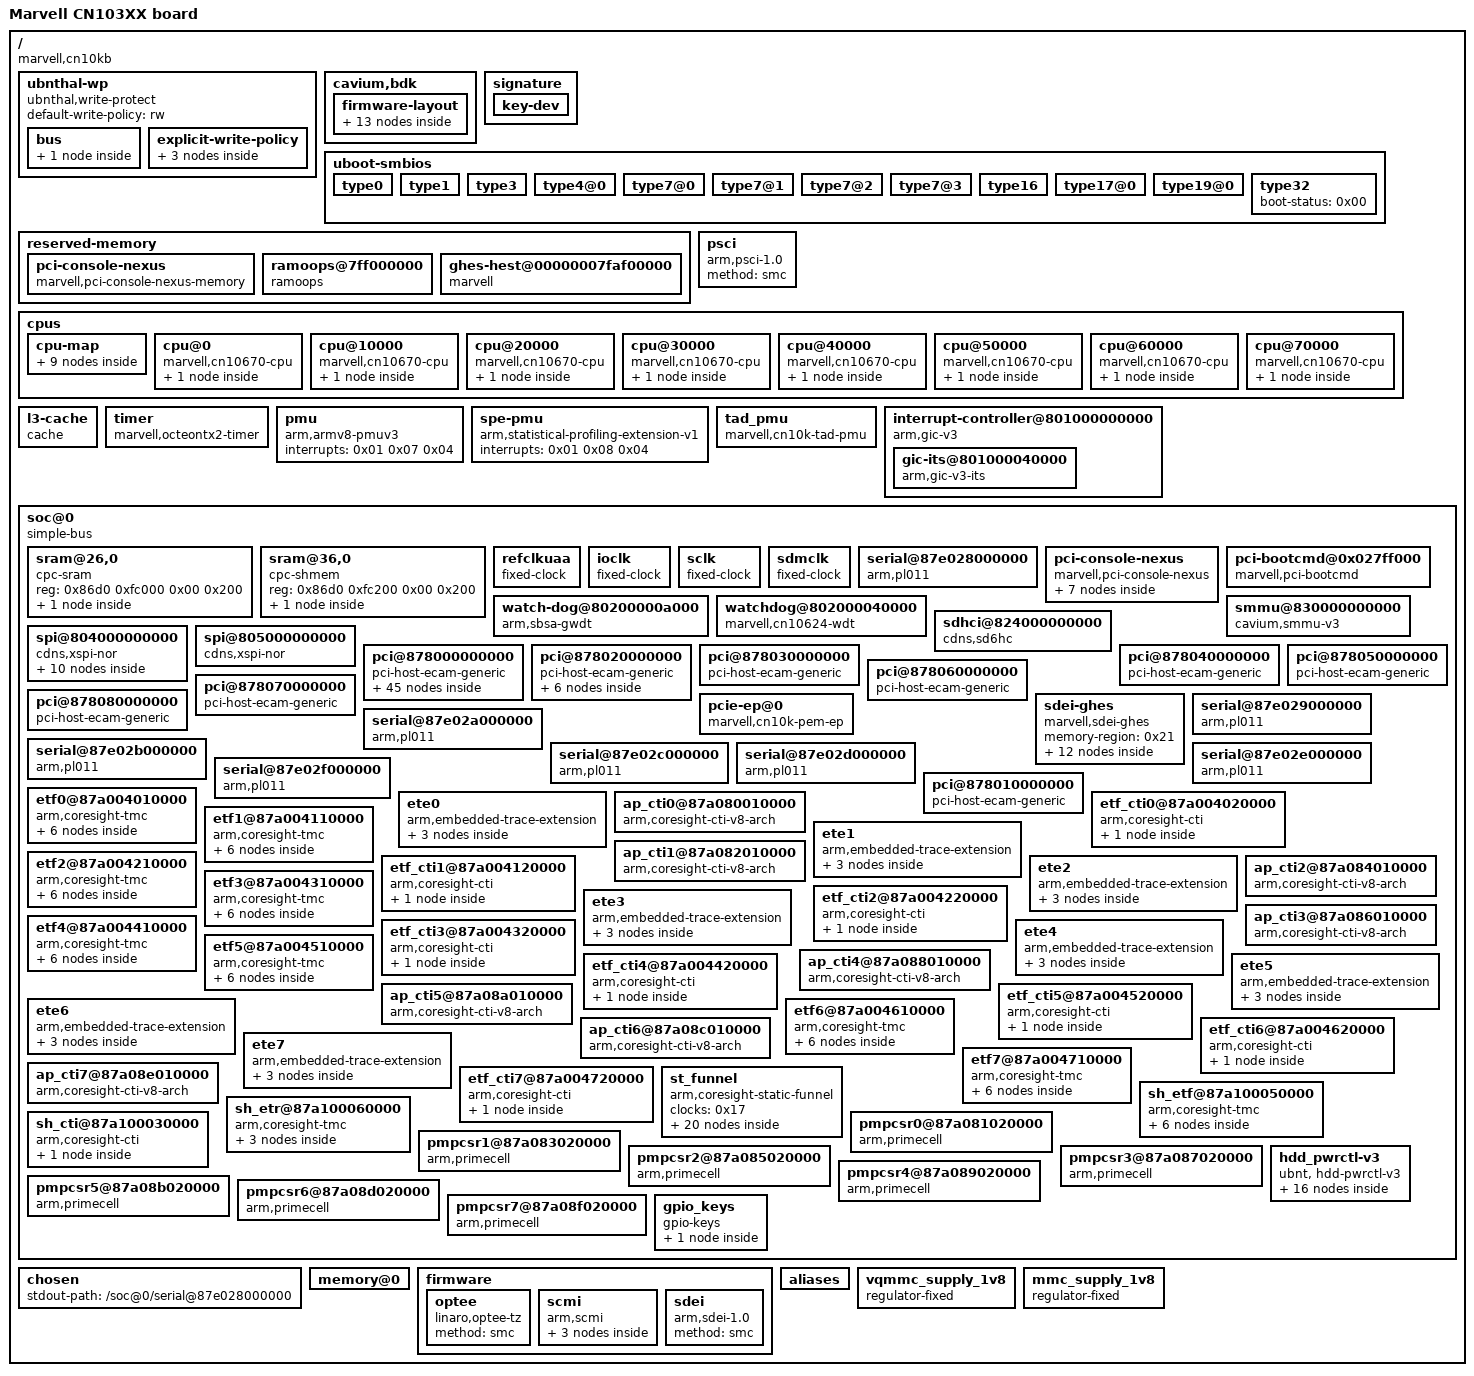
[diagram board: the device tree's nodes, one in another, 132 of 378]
/dts-v1/;

/ {
	model = "Marvell CN103XX board";
	compatible = "marvell,cn10kb";
	interrupt-parent = <0x01>;
	#address-cells = <0x02>;
	#size-cells = <0x02>;

	ubnthal-wp {
		compatible = "ubnthal,write-protect";
		default-write-policy = "rw";

		bus {

			spi@0 {
				bus = "*.spi";
				default-write-policy = "rw";
			};
		};

		explicit-write-policy {

			mtd {

				partition@0 {
					label = "Factory";
					write-policy = "ro";
				};

				partition@1 {
					label = "EEPROM";
					write-policy = "ro";
				};
			};
		};
	};

	cavium,bdk {
		TWSI0-HIDE-NSEC = "0";
		EBF-CONFIG-PCIE-DISABLE-HOST-BAR0-WINDOWING = "0";
		APA-WATCHDOG-TIMEOUT = "0";
		DDR-PRESERVE-CORESIGHT-REGION-SIZE = "0";
		UART-RX-DISABLE-UPON-BOOT = [00];
		PHASE-ADAPT-CAL = "0xf";
		LOAD-EHSM-PIE-FW = "0";
		SPI0-CS0-FLASH-SECTOR-64K = "0";
		RESET-COUNT-PERSIST = "0";
		EBF-CONFIG-ATF-TIMESTAMP = "0";
		EBF-CONFIG-ATF-TRACE-LEVEL = "0";
		EBF-CONFIG-ATF-TRACE-MODULES = "0";
		PBUS-TIM = "0";
		PBUS-CFG = "0";
		UAA0-DRIVE = "3";
		UAA0-SLEW = "3";
		TWSI0-DRIVE = "1";
		TWSI0-SLEW = "2";
		AVS-DRIVE = "3";
		AVS-SLEW = "3";
		GPIO-POLARITY-REMAP-GPIO0 = "0";
		GPIO-PIN-SELECT-REMAP-GPIO0 = "-1";
		GPIO-DRIVE = "2";
		GPIO-SLEW = "3";
		GPIO-POLARITY-GPIO0 = "0";
		GPIO-PIN-SELECT-GPIO0 = "-1";
		DIS-TAD-DQ = "0";
		MKCB-CHANNEL-LENGTH = "0";
		MKCB-CHANNEL-ADDR = "0";
		KTOM-CHANNEL-LENGTH = "0";
		KTOM-CHANNEL-ADDR = "0";
		SCP-NMI-GPIO = "-1";
		MCP-TWSI-TARGET-ADDR = "0x77";
		MCP-TWSI-TARGET-BUS = "-1";
		SCP-SAFE-MODE = "1";
		SCP-FAIL-ACTION = "0";
		SCP-FAIL-TIMEOUT = "0xa";
		SCP-ACTIVE-THRESHOLD = "0x3e8";
		SCP-WAKEUP-MODE = "1";
		SCP-FORCE-SECONDARY-BOOT = "0";
		SCP-MCP-DISABLE = "0";
		SCP-UART-REDIRECT-NUM = "0xf";
		SCP-UART-NUM = "1";
		POWER-LIMIT-GPIO-INVERT = "0";
		POWER-LIMIT-GPIO-PIN = "0";
		DVFS-THERMAL-HOT-BACKOFF = "0x32";
		DVFS-THERMAL-HOT = "0x64";
		DVFS-POWER-CONTROL-MODE = "5";
		DVFS-POWER-BUDGET = "0x64";
		VDD-SYS-COMPENSATION = "0x64";
		VDD-SYS-TOLERANCE = "0x1d";
		VDD-CORE-COMPENSATION = "0x64";
		VDD-CORE-TOLERANCE = "0x1d";
		SYNCE-MODE = "1";
		NCLK-FREQ = "0x190";
		NETCLK-FREQ = "0x320";
		IOCLK-FREQ = "0x320";
		CPTCLK-FREQ = "0x1f4";
		DSPCLK-FREQ = "0x1f4";
		BCLK-FREQ = "0x1f4";
		SCLK-FREQ-MIN = "0x1f4";
		CORECLK-FREQ-MIN = "0x1f4";
		VRM-TEMP-HIGH = "0x6e";
		VRM-TEMP-TRIP = "0x82";
		USB-RX-SIGDET-LF-THRESH-EN = "1";
		USB-RX-SIGDET-LF-THRESH = "5";
		USB-SET-SS-SPEED = "2";
		USB-TX-DEEMPH-3 = "0xf80";
		USB-TX-DEEMPH-2 = "0x8d80";
		USB-TX-DEEMPH-1 = "0xe45";
		USB-TX-DEEMPH-10G = "0x8c45";
		USB-TX-DEEMPH-5G = "0xacc0";
		USB-DISABLE-PORTS = "0";
		USB-PWR-GPIO-POLARITY = "1";
		USB-PWR-GPIO = "-1";
		DDR-DRAM-CONTROL-TEST-FLAGS = "4";
		DDR-DRAM-CONTROL-TEST-LENGTH = "0x80000000";
		DDR-DRAM-CONTROL-START-ADDR = "0";
		DDR-DRAM-TEST-SELECTIONS = "0";
		DDR-PRESERVE-ECC-CHECK = "0";
		DDR-PRESERVE-REGION-DIAG = "0";
		EBF-CONFIG-DDR5-SCRUB-EN = "0";
		DDR-MBIST-STOP-ON-UNREPAIRABLE-FAIL = "0";
		DDR-DRAM-MPPR = "0";
		DDR-DRAM-MBIST = "0";
		EBF_CONFIG_DDR5_PPR_ROW = "0x40000";
		EBF_CONFIG_DDR5_PPR_BA = "0";
		EBF_CONFIG_DDR5_PPR_BG = "0";
		EBF_CONFIG_DDR5_PPR_DEVICE = "0";
		EBF_CONFIG_DDR5_PPR_RANK = "0";
		EBF_CONFIG_DDR5_PPR_CHANNEL = "0";
		DDR-PHY-VREF-CA-SWEEP-MAX = "0x10";
		DDR-PHY-VREF-CA-SWEEP-MIN = "0x40";
		DDR-PHY-VREF-CS-SWEEP-MAX = "0x10";
		DDR-PHY-VREF-CS-SWEEP-MIN = "0x40";
		DDR-PHY-USE-LFSR0-ONLY = "0";
		DDR-PHY-REPEAT-RX-TRAIN = "0";
		DDR-PHY-CA-TRAIN-OPT = "0x10";
		DDR-PHY-IS-HIGH-VDD = "0";
		EBF-CONFIG-DDR5-ECC-EN = "1";
		DDR4-TX2D-TRAIN-OPT = "0";
		DDR4-RX2D-TRAIN-OPT = "0";
		DDR-DRAM-TYPE = "0";
		DDR4-FGR-MODE = "0";
		DDR4-VREF-DQ-VALUE = "0";
		DDR4-VREF-DQ-RANGE = "0";
		DDR4-WR-CRC = "0";
		DDR4-MEM-RTT-PARK-DUAL-RANK = "0";
		DDR4-MEM-RTT-PARK-SINGLE-RANK = "0";
		DDR4-MEM-RTT-WR-DUAL-RANK = "0";
		DDR4-MEM-RTT-WR-SINGLE-RANK = "0";
		DDR4-OUTPUT-DRV = "0";
		DDR4-MEM-RTT-NOM-DUAL-RANK = "0";
		DDR4-MEM-RTT-NOM-SINGLE-RANK = "0";
		DDR4-RD-PREAMBLE = "0";
		DDR4-WR-PREAMBLE = "0";
		DDR4-DDRC-2T-MODE = "0";
		DDR4-DDRC-T-REFI = "0";
		DDR-MCT-KEY-127-96 = "0";
		DDR-MCT-KEY-95-64 = "0";
		DDR-MCT-KEY-63-32 = "0";
		DDR-MCT-KEY-31-0 = "0";
		DDR4-MCT-CMD-TYPE = "0";
		DDR-SPD-ADDR = "0";
		DDR-PERFWR1 = "0x8000400";
		DDR-PERFLPR1 = "0x800007f";
		DDR-PERFHPR1 = "0x8000001";
		DDR-LPRNUMENTRIES = "0x3e";
		DDR-PCHBCBUSYW = "0x1408008";
		DDR-PCHBCBUSYL = "0x120600c";
		DDR-PCHBCBUSYH = "0x501c02";
		DDR-PCHBPROTQCTL = "0";
		DDR-PCHBWQOS1 = "0x380038";
		DDR-PCHBRQOS1 = "0x380038";
		DDR-PCHBWQOS0 = "0x1000a05";
		DDR-PCHBRQOS0 = "0xe00";
		DDR-PPR-EPRC-TH = "0x80";
		DDR-PPR-REPAIR-ROWS-OFF = "1";
		DDR-PPR-STAT-EN = "1";
		DDR-PPR-EN = "0";
		PORTM-SCH = "-1";
		ETHERNET-PERSIST-SETTINGS-IGNORE = "0";
		PORTM-802-3AP-FEC-REQ = "0";
		PORTM-802-3AP-FEC-ABIL = "0";
		PORTM-802-3AP-MASTER-LANE = "0";
		PORTM-LANE-TX-POST = "-1";
		PORTM-LANE-TX-PRE1 = "-1";
		PORTM-LANE-TX-PRE2 = "-1";
		PORTM-LANE-TX-MAIN = "-1";
		PORTM-LANE-TX-POLARITY = "0";
		PORTM-LANE-RX-POLARITY = "0";
		PORTM-LANE-TX-PRECODE-EN = "0";
		PORTM-LANE-RX-PRECODE-EN = "0";
		PORTM-RX-TERMINATION = "0";
		PORTM-FEC = "0";
		PORTM-MAC-TO-SERDES-MAP = "-1";
		REF-CLK-TERM = "0";
		SDP-VF-RINGS = "8";
		SDP-PF-RINGS = "8";
		PCIE-EP-HAS-PHC = "0";
		PCIE-HOST-STREAM-IDS-PEM0 = "0x30000";
		PCIE-ALLOW-HOST-TO-ACCESS-OCTEON-MEM = "0";
		PCIE-EP-SRIOV-BAR0 = "-1";
		PCIE-EP-SRIOV-DEV = "0xb903";
		PCIE-EP-NUM-VFS = "8";
		PCIE-EP-ROM-SIZE = "0";
		PCIE-EP-BAR0-SIZE = "-1";
		PCIE-EP-SUBSYS = "0xb900177d";
		PCIE-EP-REV = "0x2800000";
		PCIE-EP-ID = "0xb900177d";
		PCIE-EP-NUM-PFS = "1";
		PCIE-GEN2-LOW-SWING-MODE = "0";
		PCIE-MAX-LINK-SPEED = "GEN5";
		PCIE-RC-HOTPLUG-BUS-COUNT = "1";
		PCIE-RC-HOTPLUG = "0";
		PCIE-PHYSICAL-SLOT = "-1";
		PCIE-RC-TX-INITIAL-PRESET-GEN5 = "9";
		PCIE-RC-TX-INITIAL-PRESET-GEN4 = "5";
		PCIE-RC-TX-INITIAL-PRESET-GEN3 = "7";
		PCIE-GEN2-DEEMPHASIS = "0";
		PCIE-PRESET-REQUEST-VECTOR-GEN5 = "0x200";
		PCIE-PRESET-REQUEST-VECTOR-GEN4 = "0x20";
		PCIE-PRESET-REQUEST-VECTOR-GEN3 = "0x80";
		PCIE-ORDERING = "0";
		PCIE-ENHANCED-ALLOCATION = "1";
		SKIP-TIM-VERSION = "0";
		EBF-CONFIG-TRACE = "0";
		EBF-COREMASK = "0";
		PCIE-REF-CLOCK = "0";
		SWITCH-RESET = "1";
		SWITCH-MICROINIT = "1";
		SWITCH-DEV-INTERRUPT-PIN-SMI0 = "-1";
		SWITCH-DEV-INIT-DONE-PIN-SMI0 = "-1";
		SWITCH-SLAVE-ADDR-SMI0 = "7";
		SWITCH-SA-ALDRIN3M-PEM-PORT = "-1";
		SWITCH-SA-SMI-BUS = "-1";
		SWITCH-MCM-SMI-BUS = "-1";
		RETIMER-GSERM-MUX0 = "-1";
		WATCHDOG-TIMEOUT = "0";
		BOARD-MAC-ADDRESS-ID0 = "0";
		BOARD-MAC-ADDRESS-ID-NUM = "0";
		BOARD-MAC-ADDRESS-NUM = "0";
		BOARD-MAC-ADDRESS = "0x20fb7000000";
		BOARD-SERIAL = "unknown";
		BOARD-REVISION = "sr1";
		BOARD-MODEL = "unvr-ent";
		PCIE-EP-OVERRIDE-IDENTITY = "0";
		SCP-FAILSAFE-TIMEOUT = "60";
		DDR-SPD-ADDR.DSS0 = "0x3050";
		DDR-PRESERVE-RAMOOPS-REGION-SIZE = "16";
		DDR-PRESERVE-USERDEF-REGION-SIZE = "0";
		PORTM-MODE.P3 = "XFI";
		PORTM-MODE.P2 = "XFI";
		PORTM-MODE.P1 = "DISABLED";
		PORTM-MODE.P0 = "XFI";
		GPIO-PIN-SELECT-GPIO43 = "0x2a3";
		GPIO-PIN-SELECT-GPIO42 = "0x297";
		GPIO-PIN-SELECT-GPIO37 = "0x2a7";
		GPIO-PIN-SELECT-GPIO36 = "0x29b";
		GPIO-PIN-SELECT-GPIO35 = "0x2a6";
		GPIO-PIN-SELECT-GPIO34 = "0x29a";
		GPIO-PIN-SELECT-GPIO33 = "0x2a5";
		GPIO-PIN-SELECT-GPIO32 = "0x299";
		GPIO-PIN-SELECT-GPIO31 = "0x2a4";
		GPIO-PIN-SELECT-GPIO30 = "0x298";
		GPIO-PIN-SELECT-GPIO29 = "0x2a2";
		GPIO-PIN-SELECT-GPIO28 = "0x296";
		GPIO-PIN-SELECT-GPIO27 = "0x271";
		GPIO-PIN-SELECT-GPIO26 = "0x270";
		GPIO-PIN-SELECT-GPIO24 = "0x274";
		GPIO-PIN-SELECT-GPIO23 = "0x256";
		GPIO-PIN-SELECT-GPIO22 = "0x254";
		GPIO-PIN-SELECT-GPIO21 = "0x255";
		GPIO-PIN-SELECT-GPIO20 = "0x253";
		GPIO-PIN-SELECT-GPIO19 = "0x27b";
		GPIO-PIN-SELECT-GPIO18 = "0x27a";
		GPIO-PIN-SELECT-GPIO17 = "0x279";
		GPIO-PIN-SELECT-GPIO16 = "0x278";
		PCIE-REF-CLOCK.PORT0 = "1";
		PCIE-MAX-LINK-SPEED.PORT5 = "GEN3";
		PCIE-MAX-LINK-SPEED.PORT4 = "GEN3";
		PCIE-MAX-LINK-SPEED.PORT3 = "GEN3";
		PCIE-MAX-LINK-SPEED.PORT2 = "GEN3";
		PCIE-MAX-LINK-SPEED.PORT1 = "GEN3";
		PCIE-MAX-LINK-SPEED.PORT0 = "GEN3";
		PCIE-MODE.PORT5 = "PCIE_X1";
		PCIE-MODE.PORT1 = "PCIE_X1";
		PCIE-MODE.PORT4 = "PCIE_X1";
		PCIE-MODE.PORT3 = "PCIE_X1";
		PCIE-MODE.PORT2 = "PCIE_X1";
		PCIE-MODE.PORT0 = "PCIE_X1";
		SCLK-FREQ-MAX = "1000";
		CORECLK-FREQ-MAX = "2500";
		EBF-BOOT-MENU-TIMEOUT = "10";
		DDR5-DFE-GAIN-BIAS = "3";
		DDR5-TX2D-TRAIN-OPT = "1";
		DDR5-RX2D-TRAIN-OPT = "1";
		DDR5-MEM-RTT-NOM-RD = "3";
		DDR5-MEM-RTT-NOM-WR = "3";
		DDR5-MEM-RTT-WR-DUAL-RANK = "3";
		DDR5-MEM-RTT-WR-SINGLE-RANK = "4";
		DDR5-MEM-RTT-PARK = "7";
		DDR5-MEM-DQS-RTT-PARK = "5";
		DDR5-MEM-CA-ODT-GRP-B-DUAL-RANK = "4";
		DDR5-MEM-CA-ODT-GRP-A-DUAL-RANK = "1";
		DDR5-MEM-CA-ODT-GRP-B-SINGLE-RANK = "5";
		DDR5-MEM-CA-ODT-GRP-A-SINGLE-RANK = "2";
		DDR5-MEM-CS-ODT-GRP-B = "5";
		DDR5-MEM-CK-ODT-GRP-B = "5";
		DDR5-MEM-CS-ODT-GRP-A = "2";
		DDR5-MEM-CK-ODT-GRP-A = "2";
		DDR5-MEM-VREF-CS = "0xad";
		DDR5-MEM-VREF-CA = "0x2d";
		DDR5-MEM-VREF-DQ = "0x37";
		DDR-X16-BYTE-SWAP-BIT-MASK = "0";
		DDR-PHY-ADV-TRAIN-OPT = "0x28";
		DDR-PHYCFG-SETUP-HOLD = "0";
		DDR-PHY-TX-SLEW-FALL-CK = "0";
		DDR-PHY-TX-SLEW-RISE-CK = "0";
		DDR-PHY-TX-SLEW-FALL-AC = "1";
		DDR-PHY-TX-SLEW-RISE-AC = "1";
		DDR-PHY-TX-SLEW-FALL-DQ = "0";
		DDR-PHY-TX-SLEW-RISE-DQ = "0";
		DDR-PHY-INITIAL-VREF = "90";
		DDR-PHY-HDT-CTRL = "0xC8";
		DDR-PHY-CS-TX-IMP = "30";
		DDR-PHY-CA-TX-IMP = "30";
		DDR-PHY-CK-TX-IMP = "30";
		DDR-PHY-TX-IMP = "30";
		DDR-PHY-ODT-M_ALERT-IMP = "120";
		DDR-PHY-ODT-IMP-DUAL-RANK = "40";
		DDR-PHY-ODT-IMP-SINGLE-RANK = "60";
		DDR5-TCR-EN = "0";
		DDR5-RD-PREAMBLE = "3";
		DDR5-WR-POSTAMBLE = "1";
		DDR5-WR-PREAMBLE = "2";
		DDR5-RD-POSTAMBLE = "1";
		DDR-RD-CRC-EN = "0";
		DDR-WR-CRC-EN = "0";
		DDR5-DDRC-2N-MODE = "0";
		DDR5-REFRESH-MODE-TEMP = "0";
		DDR5-REFRESH-MODE = "1";
		DDR5-PAGE-CLOSE-TIMER = "0";
		DDR5-PAGE-CLOSE-EN = "1";
		DDR-DDRC-DATA-BUS-WIDTH = "0";
		DDR-OUTPUT-DRV-IMP = "0";
		DDR-MCT-DATA-BUS-WIDTH = "1";
		DDR-MCT-ENC-KEY-SCRAMBLE = "1";
		DDR5-MCT-BURST-CHOP-EN = "0";
		DDR5-MCT-BURST-LENGTH = "1";
		DDR-MCT-EN = "0";
		DDR-MCT-WIN-ADDR-HIGH = "0xFFFFFFFFFFFFF";
		DDR-MCT-WIN-ADDR-LOW = "0x0";
		DDR-MCT-NUM-OF-WIN = "1";
		DDR-MCT-ENCRYPTION-EN = "0";
		DDR-SPEED = "4800";
		DDR-DMC-MASK = "3";
		EBF-VERSION = "12.23.12-5550707, Branch: (HEAD detached at 5550707), Built: Mon, 11 Mar 2024 09:50:36 +0000";
		RESET-COUNT-COLD = "0";
		RESET-COUNT-WARM = "0";
		RESET-COUNT-SCP-WDOG = "0";
		RESET-COUNT-CORE-WDOG = "0";
		RESET-COUNT-MCP-WDOG = "0";
		RESET-COUNT-ECP-WDOG = "0";
		BOOT-DEVICE = "SPI0_CS0";
		EBF-BOOT-PATH-OPTION = "0";
		CHIP-SKU = "MV-CN10208-A0-HF240AG-xxxx-SCP";
		CHIP-SERIAL = " ";
		CHIP-UNIQUE-ID = "00000000000000000000";
		PCIE-EP-INITIALIZE-AFTER-MEM-CONFIG = "0";
		DDR-DMC-CH-SIZE = <0x4000 0x4000>;
		DDR-WAS-PRESERVED = "1";
		DDR-SPD-DATA.DSS0 = <0x30101203 0x4002062 0x00 0xb2120d00 0x00 0x6501f203 0x7aad0000 0x803e 0x803e803e 0x7d80bb 0x30752701 0xa0008200 0x00 0xd400 0xd400 0xd400 0xd400 0x8813 0x8881308 0x204e2010 0x2710a42c 0x20102710 0xc409044c 0x1d0c0000 0x00 0x00 0x00 0x00 0x00 0x00 0x00 0x00 0x00 0x00 0x00 0x00 0x00 0x00 0x00 0x00 0x00 0x00 0x00 0x00 0x00 0x00 0x00 0x00 0x10008632 0x80158a8c 0x82130000 0x00 0x00 0x00 0x00 0x00 0x00 0xf11 0x1820822 0x00 0x00 0x00 0x00 0x00 0x00 0x00 0x00 0x00 0x00 0x00 0x00 0x00 0x00 0x00 0x00 0x00 0x00 0x00 0x00 0x00 0x00 0x00 0x00 0x00 0x00 0x00 0x00 0x00 0x00 0x00 0x00 0x00 0x00 0x00 0x00 0x00 0x00 0x00 0x00 0x00 0x00 0x00 0x00 0x00 0x00 0x00 0x00 0x00 0x00 0x00 0x00 0x00 0x00 0x00 0x00 0x00 0x00 0x00 0x00 0x00 0x00 0x00 0x00 0x00 0x00 0x00 0x00 0x70a8 0x1980123 0x45ef075a 0xf1434244 0x35365334 0x36424438 0x48412d33 0x32202020 0x20202020 0x20202020 0x20202000 0x80ad4100 0x8313031 0x36323035 0x34000000 0x00 0x00 0x00 0x00 0x00 0x00 0x1000000 0x00 0x00 0x00 0x01 0x1000000 0x00 0x88 0x00 0x00 0x00 0x00>;

		firmware-layout {
			#size-cells = <0x01>;
			#address-cells = <0x01>;

			tee.bin@00810000 {
				reg = <0x810000 0x250000>;
				description = "tee.bin";
				os = "arm-trusted-firmware";
				arch = "arm64";
				compression = "none";
				type = "firmware";
			};

			npc_mkex-cn10xx.fw@007b0000 {
				flags = <0x00>;
				version = "01.0A.00 20240201-1636 00000000";
				customer-version = <0x00>;
				time = <0x10240000>;
				date = <0x7e80201>;
				revision = <0x10a0000>;
				reg = <0x7b0000 0x60000>;
				description = "npc_mkex-cn10xx.fw";
				compression = "none";
				type = "firmware";
			};

			u-boot-nodtb.bin@00660000 {
				flags = <0x00>;
				version = "0B.17.0C 20240111-0222 00000000";
				customer-version = <0x00>;
				time = <0x2160000>;
				date = <0x7e8010b>;
				revision = <0xb170c00>;
				reg = <0x660000 0x150000>;
				description = "u-boot-nodtb.bin";
				os = "arm-trusted-firmware";
				arch = "arm64";
				compression = "none";
				type = "firmware";
			};

			bl31.bin@00540000 {
				flags = <0x00>;
				version = "0B.17.0C 20240111-0222 00000000";
				customer-version = <0x00>;
				time = <0x2160000>;
				date = <0x7e8010b>;
				revision = <0xb170c00>;
				reg = <0x540000 0x120000>;
				description = "bl31.bin";
				os = "arm-trusted-firmware";
				arch = "arm64";
				compression = "none";
				type = "firmware";
			};

			bl2.bin@004C0000 {
				flags = <0x00>;
				version = "0B.17.0C 20240111-0222 00000000";
				customer-version = <0x00>;
				time = <0x2160000>;
				date = <0x7e8010b>;
				revision = <0xb170c00>;
				reg = <0x4c0000 0x80000>;
				description = "bl2.bin";
				os = "arm-trusted-firmware";
				arch = "arm64";
				compression = "none";
				type = "firmware";
			};

			gserp-cn10xx.fw@00490000 {
				flags = <0x00>;
				version = "01.01.0C 20240201-1636 00000000";
				customer-version = <0x00>;
				time = <0x10240000>;
				date = <0x7e80201>;
				revision = <0x1010c00>;
				reg = <0x490000 0x30000>;
				description = "gserp-cn10xx.fw";
				os = "arm-trusted-firmware";
				arch = "custom";
				compression = "none";
				type = "firmware";
			};

			gserm-cn10xx.fw@00460000 {
				flags = <0x00>;
				version = "01.01.0A 20240201-1636 00000000";
				customer-version = <0x00>;
				time = <0x10240000>;
				date = <0x7e80201>;
				revision = <0x1010a00>;
				reg = <0x460000 0x30000>;
				description = "gserm-cn10xx.fw";
				os = "arm-trusted-firmware";
				arch = "custom";
				compression = "none";
				type = "firmware";
			};

			init.bin@00100000 {
				flags = <0x00>;
				version = "0C.17.0C 20240311-0951 00000000";
				customer-version = <0x00>;
				time = "\t3", "";
				date = <0x7e8030b>;
				revision = <0xc170c00>;
				reg = <0x100000 0x360000>;
				description = "init.bin";
				os = "arm-trusted-firmware";
				arch = "arm64";
				compression = "none";
				type = "firmware";
			};

			ecp_bl1.bin@000D0000 {
				flags = <0x00>;
				version = "0C.17.0C 20231209-2323 00000000";
				customer-version = <0x00>;
				time = <0x17170000>;
				date = <0x7e70c09>;
				revision = <0xc170c00>;
				reg = <0xd0000 0x30000>;
				description = "ecp_bl1.bin";
				os = "arm-trusted-firmware";
				arch = "mips32";
				compression = "none";
				type = "firmware";
			};

			mcp_bl1.bin@000A0000 {
				flags = <0x00>;
				version = "0C.17.0C 20231209-2330 00000000";
				customer-version = <0x00>;
				time = <0x171e0000>;
				date = <0x7e70c09>;
				revision = <0xc170c00>;
				reg = <0xa0000 0x30000>;
				description = "mcp_bl1.bin";
				os = "arm-trusted-firmware";
				arch = "mips32";
				compression = "none";
				type = "firmware";
			};

			scp_bl1.bin@00040000 {
				flags = <0x00>;
				version = "0C.17.0C 20231208-2010 00000000";
				customer-version = <0x00>;
				time = <0x140a0000>;
				date = <0x7e70c08>;
				revision = <0xc170c00>;
				reg = <0x40000 0x60000>;
				description = "scp_bl1.bin";
				os = "arm-trusted-firmware";
				arch = "mips32";
				compression = "none";
				type = "firmware";
			};

			rom-script0.fw@00020000 {
				flags = <0x00>;
				version = "0C.17.0C 20240311-0950 00000000";
				customer-version = <0x00>;
				time = "\t2", "";
				date = <0x7e8030b>;
				revision = <0xc170c00>;
				reg = <0x20000 0x20000>;
				description = "rom-script0.fw";
				compression = "none";
				type = "firmware";
			};

			tim0@00010000 {
				reg = <0x10000 0x4000>;
				description = "tim0";
				compression = "none";
				root-tim-object = "scp_bl1.bin";
				type = "firmware";
			};
		};
	};

	signature {

		key-dev {
			required = "conf";
			algo = "sha256,rsa2048";
			rsa,r-squared = <0x89ff95f2 0x851bb587 0xf73d9906 0x8a55ce4f 0x9b535633 0xd1b50060 0x519953a4 0xa6de89c3 0x4f93ceb6 0xd4845ab8 0x6a3bc081 0xf356d1da 0xedbf743c 0xa7296672 0x3dd7c1db 0x14859e3c 0x4d984c27 0x42998501 0x2b4556d5 0x7a8e7b1f 0x9f8681bc 0x966ff6fd 0x134f76f4 0x70c1dda7 0xe839ddfa 0x5af49741 0x3b6752b1 0x2d234f7e 0xf47602c2 0x7f4695da 0xd0254c2d 0xb3cea6f7 0xfed03fa5 0x2bcedae2 0x63c17224 0xf99d1673 0x5d074faf 0x2ca92fe 0xfd5f1b74 0x3c5d715b 0x761379aa 0x56237e26 0x723be51e 0xdf34595c 0xe9016c3b 0x4f50afe6 0x266a287d 0x5e855a8c 0xcd8b2745 0x772b92d 0xaaebc464 0x37da0b62 0x4efa5dea 0x5cc8e2f 0x8d9f0f5f 0x19f4d6e7 0xbda3191f 0x9cf275dd 0xe888c55a 0xe430449e 0x6f715cfe 0xd57a459f 0x6484c52a 0xca47b913>;
			rsa,modulus = <0xc9bff5e6 0x60d51523 0x9a553667 0xa341c484 0x4bd352ad 0x5b3d078a 0x19d7e80c 0x1ede28ce 0x409061b5 0xa7f3871e 0x71307b7a 0x719a585e 0xd07febbb 0x6270c0b9 0x6127e435 0x2427e020 0x811f7ebc 0x59522542 0x8f7dc73c 0x681bf21c 0x3e4848bd 0xe5d184c6 0x630f188d 0x237451d3 0xfbb6454e 0x69d59c71 0xb88eb109 0x7f89f082 0xf01b7284 0xdef8c343 0xcff96b75 0xd957c637 0x95fc81de 0x8d3bc48d 0x4c0575f7 0xfe5da80a 0x667c61b5 0x97ca0df8 0x9e54c74 0x678f983c 0xbcd24561 0xe90fec13 0x343a23fa 0xef6f5943 0xa9bf696e 0xd00eba60 0x3e5c4987 0x7b459523 0xfef707ff 0x4fc21976 0xf88e474e 0xe252bd16 0x3ec667f4 0x480c3cee 0x73aef283 0x2f9296db 0x2a53ec37 0xc6c7ec80 0xfbb49de7 0xb9bbf00b 0x11a6a24 0xc5b9cd6f 0xacab004 0x61c81afd>;
			rsa,exponent = <0x00 0x10001>;
			rsa,n0-inverse = <0xe34dadab>;
			rsa,num-bits = <0x800>;
			key-name-hint = "dev";
		};
	};

	uboot-smbios {

		type0 {
			#bios-char-cells = <0x02>;
			bios-chars = <0x10880 0x00>;
			bios-chars-ext1 = <0x01>;
			bios-chars-ext2 = <0x08>;
		};

		type1 {
			manufacturer = "Marvell";
			prod-name = "CN10K";
			wakeup-type = <0x06>;
		};

		type3 {
			manufacturer = "Marvell";
			type = <0x17>;
		};

		type4@0 {
			socket = "DPU";
			processor-type = <0x03>;
			processor-family = <0xfe>;
			processor-family2 = <0x101>;
			processor-manufacturer = "Marvell";
			processor-id = <0x00>;
			processor-version = "A0";
			voltage = <0x88>;
			external-clock = <0x00>;
			maxspeed = <0x9c4>;
			curspeed = <0x9c4>;
			cpu-status = <0x41>;
			processor-upgrade = <0x06>;
			serial-number = "Unknown                       ";
			asset-tag = "Unknown                       ";
			part-number = "Unknown                       ";
			core-count = <0x08>;
			core-enabled = <0x08>;
			thread-count = <0x08>;
			processor-characteristics = <0xdc>;
		};

		type7@0 {
			socket = "Internal L1I Cache";
			cache-config = <0x180>;
			maxsize = <0x40>;
			installed-size = <0x40>;
			supported-sram = <0x28>;
			current-sram = <0x28>;
			cache-speed = <0x00>;
			ecorr-type = <0x04>;
			cache-type = <0x03>;
			associativity = <0x05>;
		};

		type7@1 {
			socket = "Internal L1D Cache";
			cache-config = <0x180>;
			maxsize = <0x40>;
			installed-size = <0x40>;
			supported-sram = <0x28>;
			current-sram = <0x28>;
			cache-speed = <0x00>;
			ecorr-type = <0x05>;
			cache-type = <0x04>;
			associativity = <0x05>;
		};

		type7@2 {
			socket = "Internal L2 Unified Cache";
			cache-config = <0x181>;
			maxsize = <0x400>;
			installed-size = <0x400>;
			supported-sram = <0x28>;
			current-sram = <0x28>;
			cache-speed = <0x00>;
			ecorr-type = <0x05>;
			cache-type = <0x05>;
			associativity = <0x07>;
		};

		type7@3 {
			socket = "Last Level Cache";
			cache-config = <0x182>;
			maxsize = <0x8100>;
			installed-size = <0x8100>;
			supported-sram = <0x28>;
			current-sram = <0x28>;
			cache-speed = <0x00>;
			ecorr-type = <0x05>;
			cache-type = <0x05>;
			associativity = <0x08>;
		};

		type16 {
			#ext-max-capacity-cells = <0x02>;
			location = <0x03>;
			use = <0x03>;
			err-corr = <0x05>;
			max-capacity = <0x80000000>;
			memerr-info = <0xfffe>;
			mem-slots = <0x03>;
			ext-max-capacitys = <0x300 0x00>;
		};

		type17@0 {
			array-handle = <0x600>;
			errinfo-handle = <0xfffe>;
			total-width = <0x40>;
			data-width = <0x40>;
			size = <0x7fff>;
			ext-size = <0x8000>;
			form-factor = <0x0d>;
			device-set = <0x00>;
			device-loc = "DDR0";
			mem-type = <0x22>;
			nonvol-size = <0x00>;
			#vol-size-cells = <0x02>;
			vol-sizes = <0x08 0x00>;
			#cache-size-cells = <0x02>;
			cache-sizes = <0xffffffff 0xffffffff>;
			#log-size-cells = <0x02>;
			log-sizes = <0x08 0x00>;
			speed = <0x15e0>;
			configured-memory-speed = <0x12c0>;
			attributes = <0x02>;
			module-product-id = <0x00>;
			minimum_voltage = <0x44c>;
			maximum_voltage = <0x44c>;
			configured_voltage = <0x44c>;
			serial-number = "Unknown Serial                ";
			module-manufacturer-id = <0x9801>;
			manufacturer = "Unknown Manufacturer          ";
			part-number = "Unknown Part                  ";
		};

		type19@0 {
			start-addr = <0xffffffff>;
			end-addr = <0xffffffff>;
			array-handle = <0x600>;
			part-width = <0x01>;
			#ext-start-addr-cells = <0x02>;
			ext-start-addrs = <0x00 0x4000000>;
			#ext-end-addr-cells = <0x02>;
			ext-end-addrs = <0x07 0xffffffff>;
		};

		type32 {
			boot-status = <0x00>;
		};
	};

	reserved-memory {
		#address-cells = <0x02>;
		#size-cells = <0x02>;
		ranges;

		pci-console-nexus {
			compatible = "marvell,pci-console-nexus-memory";
			reg = <0x00 0x20060000 0x00 0x1c100>;
			no-map;
			phandle = <0x15>;
		};

		ramoops@7ff000000 {
			compatible = "ramoops";
			reg = <0x07 0xff000000 0x00 0x1000000>;
			record-size = <0x1000>;
			console-size = <0x1000>;
			pmsg-size = <0x1000>;
			ftrace-size = <0x1000>;
			no-map;
		};

		ghes-hest@00000007faf00000 {
			compatible = "marvell";
			reg = <0x07 0xfaf00000 0x00 0x100000>;
			no-map;
			phandle = <0x21>;
		};
	};

	psci {
		compatible = "arm,psci-1.0";
		method = "smc";
	};

	cpus {
		#address-cells = <0x02>;
		#size-cells = <0x00>;

		cpu-map {

			cluster0 {

				core0 {
					cpu = <0x02>;
				};

				core1 {
					cpu = <0x03>;
				};

				core2 {
					cpu = <0x04>;
				};

				core3 {
					cpu = <0x05>;
				};

				core4 {
					cpu = <0x06>;
				};

				core5 {
					cpu = <0x07>;
				};

				core6 {
					cpu = <0x08>;
				};

				core7 {
					cpu = <0x09>;
				};
			};
		};

		cpu@0 {
			device_type = "cpu";
			compatible = "marvell,cn10670-cpu", "arm,armv8";
			reg = <0x00 0x00>;
			enable-method = "psci";
			numa-node-id = <0x00>;
			next-level-cache = <0x0a>;
			i-cache-size = <0x10000>;
			i-cache-line-size = <0x40>;
			i-cache-sets = <0x100>;
			d-cache-size = <0x10000>;
			d-cache-line-size = <0x40>;
			d-cache-sets = <0x100>;
			clocks = <0x0b 0x00>;
			phandle = <0x02>;

			l2-cache {
				compatible = "cache";
				numa-node-id = <0x00>;
				next-level-cache = <0x0c>;
				cache-unified;
				cache-level = <0x02>;
				cache-size = <0x100000>;
				cache-line-size = <0x40>;
				cache-sets = <0x800>;
				phandle = <0x0a>;
			};
		};

		cpu@10000 {
			device_type = "cpu";
			compatible = "marvell,cn10670-cpu", "arm,armv8";
			reg = <0x00 0x10000>;
			enable-method = "psci";
			numa-node-id = <0x00>;
			next-level-cache = <0x0d>;
			i-cache-size = <0x10000>;
			i-cache-line-size = <0x40>;
			i-cache-sets = <0x100>;
			d-cache-size = <0x10000>;
			d-cache-line-size = <0x40>;
			d-cache-sets = <0x100>;
			clocks = <0x0b 0x01>;
			phandle = <0x03>;

			l2-cache {
				compatible = "cache";
				numa-node-id = <0x00>;
				next-level-cache = <0x0c>;
				cache-unified;
				cache-level = <0x02>;
				cache-size = <0x100000>;
				cache-line-size = <0x40>;
				cache-sets = <0x800>;
				phandle = <0x0d>;
			};
		};

		cpu@20000 {
			device_type = "cpu";
			compatible = "marvell,cn10670-cpu", "arm,armv8";
			reg = <0x00 0x20000>;
			enable-method = "psci";
			numa-node-id = <0x00>;
			next-level-cache = <0x0e>;
			i-cache-size = <0x10000>;
			i-cache-line-size = <0x40>;
			i-cache-sets = <0x100>;
			d-cache-size = <0x10000>;
			d-cache-line-size = <0x40>;
			d-cache-sets = <0x100>;
			clocks = <0x0b 0x02>;
			phandle = <0x04>;

			l2-cache {
				compatible = "cache";
				numa-node-id = <0x00>;
				next-level-cache = <0x0c>;
				cache-unified;
				cache-level = <0x02>;
				cache-size = <0x100000>;
				cache-line-size = <0x40>;
				cache-sets = <0x800>;
				phandle = <0x0e>;
			};
		};

		cpu@30000 {
			device_type = "cpu";
			compatible = "marvell,cn10670-cpu", "arm,armv8";
			reg = <0x00 0x30000>;
			enable-method = "psci";
			numa-node-id = <0x00>;
			next-level-cache = <0x0f>;
			i-cache-size = <0x10000>;
			i-cache-line-size = <0x40>;
			i-cache-sets = <0x100>;
			d-cache-size = <0x10000>;
			d-cache-line-size = <0x40>;
			d-cache-sets = <0x100>;
			clocks = <0x0b 0x03>;
			phandle = <0x05>;

			l2-cache {
				compatible = "cache";
				numa-node-id = <0x00>;
				next-level-cache = <0x0c>;
				cache-unified;
				cache-level = <0x02>;
				cache-size = <0x100000>;
				cache-line-size = <0x40>;
				cache-sets = <0x800>;
				phandle = <0x0f>;
			};
		};

		cpu@40000 {
			device_type = "cpu";
			compatible = "marvell,cn10670-cpu", "arm,armv8";
			reg = <0x00 0x40000>;
			enable-method = "psci";
			numa-node-id = <0x00>;
			next-level-cache = <0x10>;
			i-cache-size = <0x10000>;
			i-cache-line-size = <0x40>;
			i-cache-sets = <0x100>;
			d-cache-size = <0x10000>;
			d-cache-line-size = <0x40>;
			d-cache-sets = <0x100>;
			clocks = <0x0b 0x04>;
			phandle = <0x06>;

			l2-cache {
				compatible = "cache";
				numa-node-id = <0x00>;
				next-level-cache = <0x0c>;
				cache-unified;
				cache-level = <0x02>;
				cache-size = <0x100000>;
				cache-line-size = <0x40>;
				cache-sets = <0x800>;
				phandle = <0x10>;
			};
		};

		cpu@50000 {
			device_type = "cpu";
			compatible = "marvell,cn10670-cpu", "arm,armv8";
			reg = <0x00 0x50000>;
			enable-method = "psci";
			numa-node-id = <0x00>;
			next-level-cache = <0x11>;
			i-cache-size = <0x10000>;
			i-cache-line-size = <0x40>;
			i-cache-sets = <0x100>;
			d-cache-size = <0x10000>;
			d-cache-line-size = <0x40>;
			d-cache-sets = <0x100>;
			clocks = <0x0b 0x05>;
			phandle = <0x07>;

			l2-cache {
				compatible = "cache";
				numa-node-id = <0x00>;
				next-level-cache = <0x0c>;
				cache-unified;
				cache-level = <0x02>;
				cache-size = <0x100000>;
				cache-line-size = <0x40>;
				cache-sets = <0x800>;
				phandle = <0x11>;
			};
		};

		cpu@60000 {
			device_type = "cpu";
			compatible = "marvell,cn10670-cpu", "arm,armv8";
			reg = <0x00 0x60000>;
			enable-method = "psci";
			numa-node-id = <0x00>;
			next-level-cache = <0x12>;
			i-cache-size = <0x10000>;
			i-cache-line-size = <0x40>;
			i-cache-sets = <0x100>;
			d-cache-size = <0x10000>;
			d-cache-line-size = <0x40>;
			d-cache-sets = <0x100>;
			clocks = <0x0b 0x06>;
			phandle = <0x08>;

			l2-cache {
				compatible = "cache";
				numa-node-id = <0x00>;
				next-level-cache = <0x0c>;
				cache-unified;
				cache-level = <0x02>;
				cache-size = <0x100000>;
				cache-line-size = <0x40>;
				cache-sets = <0x800>;
				phandle = <0x12>;
			};
		};

		cpu@70000 {
			device_type = "cpu";
			compatible = "marvell,cn10670-cpu", "arm,armv8";
			reg = <0x00 0x70000>;
			enable-method = "psci";
			numa-node-id = <0x00>;
			next-level-cache = <0x13>;
			i-cache-size = <0x10000>;
			i-cache-line-size = <0x40>;
			i-cache-sets = <0x100>;
			d-cache-size = <0x10000>;
			d-cache-line-size = <0x40>;
			d-cache-sets = <0x100>;
			clocks = <0x0b 0x07>;
			phandle = <0x09>;

			l2-cache {
				compatible = "cache";
				numa-node-id = <0x00>;
				next-level-cache = <0x0c>;
				cache-unified;
				cache-level = <0x02>;
				cache-size = <0x100000>;
				cache-line-size = <0x40>;
				cache-sets = <0x800>;
				phandle = <0x13>;
			};
		};
	};

	l3-cache {
		compatible = "cache";
		numa-node-id = <0x00>;
		cache-level = <0x03>;
		cache-unified;
		cache-size = <0x1000000>;
		cache-line-size = <0x80>;
		cache-sets = <0x4000>;
		phandle = <0x0c>;
	};

	timer {
		compatible = "marvell,octeontx2-timer", "arm,armv8-timer";
		#address-cells = <0x02>;
		#size-cells = <0x02>;
		reg = <0x8020 0x00 0x00 0xf000000>;
		interrupts = <0x01 0x0d 0x04 0x01 0x0e 0x04 0x01 0x0b 0x04 0x01 0x0a 0x04>;
	};

	pmu {
		compatible = "arm,armv8-pmuv3";
		interrupts = <0x01 0x07 0x04>;
	};

	spe-pmu {
		compatible = "arm,statistical-profiling-extension-v1";
		interrupts = <0x01 0x08 0x04>;
	};

	tad_pmu {
		compatible = "marvell,cn10k-tad-pmu";
		marvell,tad-cnt = <0x10>;
		marvell,tad-page-size = <0x1000000>;
		marvell,tad-pmu-page-size = <0x1000>;
		reg = <0x87e2 0x80000000 0x00 0x10000000>;
	};

	interrupt-controller@801000000000 {
		compatible = "arm,gic-v3";
		#interrupt-cells = <0x03>;
		#address-cells = <0x02>;
		#size-cells = <0x02>;
		#redistributor-regions = <0x01>;
		ranges;
		interrupt-controller;
		reg = <0x8010 0x00 0x00 0x40000 0x8010 0x80000 0x00 0x600000 0x8010 0x680000 0x00 0x10000>;
		interrupts = <0x01 0x09 0x04>;
		phandle = <0x01>;

		gic-its@801000040000 {
			compatible = "arm,gic-v3-its";
			reg = <0x8010 0x40000 0x00 0x40000>;
			msi-controller;
			numa-node-id = <0x00>;
			#msi-cells = <0x01>;
			phandle = <0x18>;
		};
	};

	soc@0 {
		compatible = "simple-bus";
		runplatform = "HW_PLATFORM";
		chiprevision = "A0";
		sdk-version = "SDK12.23.12";
		#address-cells = <0x02>;
		#size-cells = <0x02>;
		reg = <0x00 0x00 0x00 0x00>;
		ranges;
		numa-node-id = <0x00>;
		phandle = <0x62>;

		sram@26,0 {
			compatible = "cpc-sram";
			reg = <0x86d0 0xfc000 0x00 0x200>;
			#address-cells = <0x02>;
			#size-cells = <0x01>;
			ranges = <0x00 0x00 0x86d0 0xfc000 0x200>;

			scp-shmem@0 {
				compatible = "arm,scmi-shmem";
				reg = <0x00 0x00 0x200>;
				phandle = <0x61>;
			};
		};

		sram@36,0 {
			compatible = "cpc-shmem";
			reg = <0x86d0 0xfc200 0x00 0x200>;
			#address-cells = <0x02>;
			#size-cells = <0x01>;
			ranges = <0x00 0x00 0x86d0 0xfc200 0x200>;

			scp-shmem@0 {
				compatible = "cpc-shmem";
				reg = <0x00 0x00 0x200>;
				phandle = <0x20>;
			};
		};

		refclkuaa {
			compatible = "fixed-clock";
			#clock-cells = <0x00>;
			clock-frequency = <0xfe502a>;
			clock-output-names = "refclkuaa";
			phandle = <0x14>;
		};

		ioclk {
			compatible = "fixed-clock";
			#clock-cells = <0x00>;
			clock-frequency = <0x2faf0800>;
			clock-output-names = "ioclk";
			phandle = <0x63>;
		};

		sclk {
			compatible = "fixed-clock";
			#clock-cells = <0x00>;
			clock-frequency = <0x3b9aca00>;
			clock-output-names = "sclk";
			phandle = <0x17>;
		};

		sdmclk {
			compatible = "fixed-clock";
			#clock-cells = <0x00>;
			clock-frequency = <0xbebc200>;
			clock-output-names = "sdmclk";
			phandle = <0x19>;
		};

		serial@87e028000000 {
			compatible = "arm,pl011", "arm,primecell";
			reg = <0x87e0 0x28000000 0x00 0x1000>;
			interrupts = <0x00 0x00 0x04>;
			clocks = <0x14>;
			clock-names = "apb_pclk";
			skip-init;
			phandle = <0x64>;
		};

		pci-console-nexus {
			compatible = "marvell,pci-console-nexus";
			status = "okay";
			#address-cells = <0x02>;
			#size-cells = <0x01>;
			skip-init;
			memory-region = <0x15>;
			num-consoles = <0x07>;
			reg = <0x00 0x20060000 0x00 0x1c100>;
			ranges = <0x00 0x00 0x00 0x20060100 0x4000 0x01 0x00 0x00 0x20064100 0x4000 0x02 0x00 0x00 0x20068100 0x4000 0x03 0x00 0x00 0x2006c100 0x4000 0x04 0x00 0x00 0x20070100 0x4000 0x05 0x00 0x00 0x20074100 0x4000 0x06 0x00 0x00 0x20078100 0x4000>;

			pci-console@0 {
				compatible = "marvell,pci-console";
				status = "okay";
				reg = <0x00 0x00 0x4000>;
				tx-buffer-size = <0x3000>;
				rx-buffer-size = <0xf80>;
			};

			pci-console@1 {
				compatible = "marvell,pci-console";
				status = "okay";
				reg = <0x01 0x00 0x4000>;
				tx-buffer-size = <0x3000>;
				rx-buffer-size = <0xf80>;
			};

			pci-console@2 {
				compatible = "marvell,pci-console";
				status = "okay";
				reg = <0x02 0x00 0x4000>;
				tx-buffer-size = <0x3000>;
				rx-buffer-size = <0xf80>;
			};

			pci-console@3 {
				compatible = "marvell,pci-console";
				status = "okay";
				reg = <0x03 0x00 0x4000>;
				tx-buffer-size = <0x3000>;
				rx-buffer-size = <0xf80>;
			};

			pci-console@4 {
				compatible = "marvell,pci-console";
				status = "okay";
				reg = <0x04 0x00 0x4000>;
				tx-buffer-size = <0x3000>;
				rx-buffer-size = <0xf80>;
			};

			pci-console@5 {
				compatible = "marvell,pci-console";
				status = "okay";
				reg = <0x05 0x00 0x4000>;
				tx-buffer-size = <0x3000>;
				rx-buffer-size = <0xf80>;
			};

			pci-console@6 {
				compatible = "marvell,pci-console";
				status = "okay";
				reg = <0x06 0x00 0x4000>;
				tx-buffer-size = <0x3000>;
				rx-buffer-size = <0xf80>;
			};
		};

		pci-bootcmd@0x027ff000 {
			compatible = "marvell,pci-bootcmd";
			reg = <0x00 0x27ff000 0x00 0x1000>;
			skip-init;
			phandle = <0x66>;
		};

		watch-dog@80200000a000 {
			compatible = "arm,sbsa-gwdt";
			reg = <0x8020 0xa0000 0x00 0x1000 0x8020 0xb0000 0x00 0x1000>;
			interrupts = <0x00 0x08 0x04>;
			clocks = <0x17>;
			clock-names = "ref_clk";
		};

		watchdog@802000040000 {
			compatible = "marvell,cn10624-wdt";
			reg = <0x8020 0x40000 0x00 0x20000>;
			interrupts = <0x00 0x60 0x01>;
			clocks = <0x17>;
			clock-names = "ref_clk";
			marvell,wdt-timer-index = <0x3f>;
		};

		smmu@830000000000 {
			compatible = "cavium,smmu-v3", "arm,smmu-v3";
			reg = <0x8300 0x00 0x00 0x20000>;
			dma-coherent;
			msi-parent = <0x18 0x18>;
			#iommu-cells = <0x01>;
			phandle = <0x1a>;
		};

		sdhci@824000000000 {
			compatible = "cdns,sd6hc";
			#address-cells = <0x02>;
			#size-cells = <0x02>;
			reg = <0x8240 0x00 0x00 0xa000000>;
			interrupts = <0x00 0x41 0x04>;
			dma-coherent;
			clocks = <0x19>;
			clock-names = "sdmclk";
			iommus = <0x1a 0x58>;
			sdhci-caps-mask = <0xff0000 0x00>;
			sdhci-caps = <0x80000077 0x1f6ec8a0>;
			cdns,iocell_input_delay = <0x28a>;
			cdns,iocell_output_delay = <0x708>;
			cdns,delay_element = <0x18>;
			cdns,mode = "emmc_sdr";
			bus-width = <0x08>;
			max-frequency = <0xbebc200>;
			cap-mmc-highspeed;
			mmc-hs200-1_8v;
			mmc-hs400-1_8v;
			mmc-hs400-enhanced-strobe;
			no-sdio;
			no-sd;
			vmmc-supply = <0x1b>;
			vqmmc-supply = <0x1c>;
			non-removable;
			phandle = <0x67>;
		};

		spi@804000000000 {
			compatible = "cdns,xspi-nor";
			#address-cells = <0x02>;
			#size-cells = <0x02>;
			reg = <0x8040 0x00 0x00 0x1040 0x8040 0x10000000 0x00 0x1000 0x8040 0x2000 0x00 0x2300 0x8040 0x8000 0x00 0x240>;
			iommus = <0x1a 0x30>;
			reg-names = "io", "sdma", "aux", "xfer";
			interrupts = <0x00 0x4a 0x01>;
			cdns,read-size = <0x01>;
			dma-coherent;
			phandle = <0x68>;

			flash@0 {
				compatible = "jedec,spi-nor", "spi-flash";
				reg = <0x00>;
				spi-max-frequency = <0x17d7840>;
				#address-cells = <0x01>;
				#size-cells = <0x01>;
				spi-rx-bus-width = <0x04>;
				spi-tx-bus-width = <0x04>;
				u-boot,env;
				u-boot,env-offset = <0xe20000>;
				phandle = <0x69>;

				partition@0 {
					reg = <0x00 0xa60000>;
					label = "u-boot image";
				};

				partition@1 {
					reg = <0x00 0x4c0000>;
					label = "Preloader";
				};

				partition@2 {
					reg = <0x4c0000 0x1a0000>;
					label = "ATF";
				};

				partition@3 {
					reg = <0x660000 0x400000>;
					label = "u-boot";
				};

				partition@4 {
					reg = <0xe20000 0x10000>;
					label = "u-boot env";
				};

				partition@5 {
					reg = <0xe30000 0x10000>;
					label = "u-boot env redundant";
				};

				partition@6 {
					reg = <0xe40000 0x40000>;
					label = "Factory";
					read-only;
				};

				partition@7 {
					reg = <0xe80000 0x10000>;
					label = "EEPROM";
					read-only;
				};

				partition@8 {
					reg = <0xe90000 0x100000>;
					label = "config";
				};
			};
		};

		spi@805000000000 {
			compatible = "cdns,xspi-nor";
			#address-cells = <0x02>;
			#size-cells = <0x02>;
			reg = <0x8050 0x00 0x00 0x1040 0x8050 0x10000000 0x00 0x1000 0x8050 0x2000 0x00 0x2300 0x8050 0x8000 0x00 0x240>;
			iommus = <0x1a 0x38>;
			reg-names = "io", "sdma", "aux", "xfer";
			interrupts = <0x00 0x4b 0x01>;
			cdns,read-size = <0x01>;
			dma-coherent;
			phandle = <0x6a>;
		};

		pci@878000000000 {
			compatible = "pci-host-ecam-generic";
			device_type = "pci";
			msi-map = <0x00 0x18 0x00 0x10000>;
			bus-range = <0x00 0xff>;
			#size-cells = <0x02>;
			#address-cells = <0x03>;
			dma-coherent;
			linux,pci-domain = <0x00>;
			reg = <0x8780 0x00 0x00 0x10000000>;
			iommu-map = <0x00 0x1a 0x00 0x10000>;
			ranges = <0x3000000 0x8020 0x00 0x8020 0x00 0xd0 0x900000 0x3000000 0x8280 0x00 0x8280 0x00 0x01 0x200000 0x3000000 0x82c0 0x00 0x82c0 0x00 0x00 0x200000 0x3000000 0x86d0 0x00 0x86d0 0x00 0x00 0x100000 0x3000000 0x86e0 0x00 0x86e0 0x00 0x02 0x30000000 0x3000000 0x87e0 0x2000000 0x87e0 0x2000000 0x00 0x26000000 0x3000000 0x87e0 0x3c000000 0x87e0 0x3c000000 0x00 0x18600000 0x3000000 0x87e0 0x87000000 0x87e0 0x87000000 0x00 0x76000000 0x3000000 0x87e0 0x80000000 0x87e0 0x80000000 0x00 0x1000000 0x3000000 0x87e1 0x00 0x87e1 0x00 0x00 0xc000000>;
			phandle = <0x6b>;

			mrml-bridge0@1,0 {
				compatible = "pci-bridge", "cavium,thunder-8890-mrml-bridge";
				#size-cells = <0x02>;
				#address-cells = <0x03>;
				ranges = <0x3000000 0x87e0 0x00 0x3000000 0x87e0 0x00 0x10 0x00>;
				reg = <0x800 0x00 0x00 0x00 0x00>;
				device_type = "pci";
				u-boot,dm-pre-reloc;
				phandle = <0x6c>;

				mdio-nexus@1,3 {
					compatible = "cavium,thunder-8890-mdio-nexus";
					#address-cells = <0x02>;
					#size-cells = <0x02>;
					reg = <0xb00 0x00 0x00 0x00 0x00>;
					assigned-addresses = <0x3000000 0x87e0 0x5000000 0x00 0x100000>;
					ranges = <0x87e0 0x5000000 0x3000000 0x87e0 0x5000000 0x00 0x100000>;

					mdio0@87e005003800 {
						compatible = "cavium,thunder-8890-mdio";
						#address-cells = <0x01>;
						#size-cells = <0x00>;
						reg = <0x87e0 0x5003800 0x00 0x30>;
						phandle = <0x1d>;
					};

					mdio1@87e005003880 {
						compatible = "cavium,thunder-8890-mdio";
						#address-cells = <0x01>;
						#size-cells = <0x00>;
						reg = <0x87e0 0x5003880 0x00 0x30>;
						phandle = <0x1e>;

						xfi10 {
							qlm-mode = "0x010,xfi";
							reg = <0x00>;
							compatible = "aquantia,aqr105", "ethernet-phy-ieee802.3-c45";
							phandle = <0x1f>;
						};
					};

					mdio0_uio {
						compatible = "marvell,mvmdio-uio";
						mii-bus = <0x1d>;
					};

					mdio1_uio {
						compatible = "marvell,mvmdio-uio";
						mii-bus = <0x1e>;
					};
				};

				i2c@24,0 {
					#address-cells = <0x01>;
					#size-cells = <0x00>;
					compatible = "cavium,thunder-8890-twsi", "cavium,thunderx-i2c";
					reg = <0xc000 0x00 0x00 0x00 0x00>;
					clock-frequency = <0x186a0>;
					clocks = <0x17>;
					u-boot,dm-pre-reloc;
					phandle = <0x6d>;

					pca9575@23 {
						compatible = "nxp,pca9575";
						reg = <0x23>;
						gpio-controller;
						#gpio-cells = <0x02>;
						gpio-line-names = "PSU1_ON", "PSU1_Smart_On", "PSU1_AC_OK", "PSU1_DC_OK", "PSU1_SMBAlert", "PSU1_Present", "TP13", "TP14", "PSU2_ON", "PSU2_Smart_On", "PSU2_AC_OK", "PSU2_DC_OK", "PSU2_SMBAlert", "PSU2_Present", "TP15", "TP16";
						phandle = <0x6e>;
					};
				};

				i2c@24,1 {
					#address-cells = <0x01>;
					#size-cells = <0x00>;
					compatible = "cavium,thunder-8890-twsi", "cavium,thunderx-i2c";
					reg = <0xc100 0x00 0x00 0x00 0x00>;
					clock-frequency = <0x186a0>;
					clocks = <0x17>;
					u-boot,dm-pre-reloc;
					phandle = <0x6f>;

					i2c_mux@72 {
						compatible = "pca9546";
						reg = <0x72>;
						i2c-mux-idle-disconnect;

						i2c@0 {
							reg = <0x00>;

							adt7475@2e {
								compatible = "adi,adt7475";
								reg = <0x2e>;
							};
						};

						i2c@1 {
							reg = <0x01>;

							adt7475@2e {
								compatible = "adi,adt7475";
								reg = <0x2e>;
							};
						};

						i2c@2 {
							reg = <0x02>;

							s35390a@30 {
								compatible = "sii,s35390a";
								reg = <0x30>;
								phandle = <0x70>;
							};
						};
					};
				};

				i2c@24,2 {
					#address-cells = <0x01>;
					#size-cells = <0x00>;
					compatible = "cavium,thunder-8890-twsi", "cavium,thunderx-i2c";
					reg = <0xc200 0x00 0x00 0x00 0x00>;
					clock-frequency = <0x186a0>;
					clocks = <0x17>;
					u-boot,dm-pre-reloc;
					phandle = <0x71>;

					i2c_mux@70 {
						compatible = "pca9548";
						reg = <0x70>;
						#address-cells = <0x01>;
						#size-cells = <0x00>;
						i2c-mux-idle-disconnect;

						i2c@4 {
							#address-cells = <0x01>;
							#size-cells = <0x00>;
							reg = <0x04>;

							pca9575@24 {
								compatible = "nxp,pca9575";
								gpio-controller;
								reg = <0x24>;
								#gpio-cells = <0x02>;
								baseidx = <0x1d0>;
								phandle = <0x72>;
							};

							pca9575@25 {
								compatible = "nxp,pca9575";
								reg = <0x25>;
								gpio-controller;
								#gpio-cells = <0x02>;
								baseidx = <0x1c0>;
								phandle = <0x73>;
							};

							pca9575@26 {
								compatible = "nxp,pca9575";
								reg = <0x26>;
								gpio-controller;
								#gpio-cells = <0x02>;
								baseidx = <0x1b0>;
								phandle = <0x74>;
							};

							pca9575@27 {
								compatible = "nxp,pca9575";
								reg = <0x27>;
								gpio-controller;
								#gpio-cells = <0x02>;
								baseidx = <0x1a0>;
								phandle = <0x75>;
							};

							ina230@40 {
								compatible = "ti,ina230";
								reg = <0x40>;
								shunt-resistor = <0x1388>;
							};
						};

						i2c@5 {
							#address-cells = <0x01>;
							#size-cells = <0x00>;
							reg = <0x05>;

							pca9575@28 {
								compatible = "nxp,pca9575";
								reg = <0x28>;
								gpio-controller;
								#gpio-cells = <0x02>;
								gpio-line-names = "BP_L_RESET_L", "BP_L_IO_A0", "BP_L_IO1_INT_N", "BP_L_IO2_INT_N", "BP_R_RESET_L", "BP_R_IO_A0", "BP_R_IO1_INT_N", "BP_R_IO2_INT_N", "PANEL_PRSNT_N", "AQ_INT_N", "AQR113_RESET_N", "IRQ_RTC_3V3_L", "PANEL_PRSNT_N", "SYS_WHITE_LED_N", "SYS_BLUE_LED_N", "12V_OUT_OC";
								phandle = <0x76>;
							};
						};
					};
				};

				i2c@24,3 {
					#address-cells = <0x01>;
					#size-cells = <0x00>;
					compatible = "cavium,thunder-8890-twsi", "cavium,thunderx-i2c";
					reg = <0xc300 0x00 0x00 0x00 0x00>;
					clock-frequency = <0x186a0>;
					clocks = <0x17>;
					u-boot,dm-pre-reloc;
					phandle = <0x77>;
				};

				i2c@24,4 {
					#address-cells = <0x01>;
					#size-cells = <0x00>;
					compatible = "cavium,thunder-8890-twsi", "cavium,thunderx-i2c";
					reg = <0xc400 0x00 0x00 0x00 0x00>;
					clock-frequency = <0x186a0>;
					clocks = <0x17>;
					u-boot,dm-pre-reloc;
					phandle = <0x78>;

					i2c_mux@71 {
						compatible = "pca9546";
						reg = <0x71>;
						#address-cells = <0x01>;
						#size-cells = <0x00>;
						i2c-mux-idle-disconnect;

						i2c@0 {
							#address-cells = <0x01>;
							#size-cells = <0x00>;
							reg = <0x00>;
						};

						i2c@1 {
							#address-cells = <0x01>;
							#size-cells = <0x00>;
							reg = <0x01>;
						};

						i2c@2 {
							#address-cells = <0x01>;
							#size-cells = <0x00>;
							reg = <0x02>;
						};

						i2c@3 {
							#address-cells = <0x01>;
							#size-cells = <0x00>;
							reg = <0x03>;

							pca9555@20 {
								compatible = "nxp,pca9555";
								reg = <0x20>;
								gpio-controller;
								#gpio-cells = <0x02>;
								phandle = <0x79>;
							};
						};
					};

					pca9575@27 {
						compatible = "nxp,pca9575";
						reg = <0x27>;
						gpio-controller;
						#gpio-cells = <0x02>;
						phandle = <0x7a>;
					};
				};

				i2c@24,5 {
					#address-cells = <0x01>;
					#size-cells = <0x00>;
					compatible = "cavium,thunder-8890-twsi", "cavium,thunderx-i2c";
					reg = <0xc500 0x00 0x00 0x00 0x00>;
					clock-frequency = <0x186a0>;
					clocks = <0x17>;
					u-boot,dm-pre-reloc;
					phandle = <0x7b>;
				};

				i2c@24,6 {
					#address-cells = <0x01>;
					#size-cells = <0x00>;
					compatible = "cavium,thunder-8890-twsi", "cavium,thunderx-i2c";
					reg = <0xc600 0x00 0x00 0x00 0x00>;
					clock-frequency = <0x186a0>;
					clocks = <0x17>;
					u-boot,dm-pre-reloc;
					phandle = <0x7c>;
				};

				i2c@24,7 {
					#address-cells = <0x01>;
					#size-cells = <0x00>;
					compatible = "cavium,thunder-8890-twsi", "cavium,thunderx-i2c";
					reg = <0xc700 0x00 0x00 0x00 0x00>;
					clock-frequency = <0x186a0>;
					clocks = <0x17>;
					u-boot,dm-pre-reloc;
					phandle = <0x7d>;
				};

				i2c@24,8 {
					#address-cells = <0x01>;
					#size-cells = <0x00>;
					compatible = "cavium,thunder-8890-twsi", "cavium,thunderx-i2c";
					reg = <0xc800 0x00 0x00 0x00 0x00>;
					clock-frequency = <0x186a0>;
					clocks = <0x17>;
					u-boot,dm-pre-reloc;
					status = "dsabled";
					phandle = <0x7e>;
				};

				i2c@24,9 {
					#address-cells = <0x01>;
					#size-cells = <0x00>;
					compatible = "cavium,thunder-8890-twsi", "cavium,thunderx-i2c";
					reg = <0xc900 0x00 0x00 0x00 0x00>;
					clock-frequency = <0x186a0>;
					clocks = <0x17>;
					u-boot,dm-pre-reloc;
					status = "dsabled";
					phandle = <0x7f>;
				};

				i2c@24,10 {
					#address-cells = <0x01>;
					#size-cells = <0x00>;
					compatible = "cavium,thunder-8890-twsi", "cavium,thunderx-i2c";
					reg = <0xca00 0x00 0x00 0x00 0x00>;
					clock-frequency = <0x186a0>;
					clocks = <0x17>;
					u-boot,dm-pre-reloc;
					status = "dsabled";
					phandle = <0x80>;
				};

				i2c@24,11 {
					#address-cells = <0x01>;
					#size-cells = <0x00>;
					compatible = "cavium,thunder-8890-twsi", "cavium,thunderx-i2c";
					reg = <0xcb00 0x00 0x00 0x00 0x00>;
					clock-frequency = <0x186a0>;
					clocks = <0x17>;
					u-boot,dm-pre-reloc;
					status = "dsabled";
					phandle = <0x81>;
				};
			};

			gpio0@17,0 {
				#gpio-cells = <0x02>;
				compatible = "cavium,thunder-8890-gpio";
				gpio-controller;
				reg = <0x8800 0x00 0x00 0x00 0x00>;
				u-boot,dm-pre-reloc;
				phandle = <0x88>;
			};

			mailbox@28,0 {
				#mbox-cells = <0x01>;
				compatible = "marvell,mbox";
				reg = <0xe000 0x00 0x00 0x00 0x00>;
				shmem = <0x20>;
				phandle = <0x60>;
			};
		};

		pci@878020000000 {
			compatible = "pci-host-ecam-generic";
			device_type = "pci";
			msi-map = <0x00 0x18 0x20000 0x10000>;
			bus-range = <0x00 0xff>;
			#size-cells = <0x02>;
			#address-cells = <0x03>;
			dma-coherent;
			linux,pci-domain = <0x02>;
			reg = <0x8780 0x20000000 0x00 0x10000000>;
			iommu-map = <0x00 0x1a 0x20000 0x10000>;
			ranges = <0x3000000 0x8400 0x00 0x8400 0x00 0x1f5 0x00 0x3000000 0x07 0xfb000000 0x07 0xfb000000 0x00 0x32c0000>;
			phandle = <0x89>;

			rvu-admin@0 {
				num-rvu-vfs = <0x10>;
				num-msix-vec = <0x26>;
			};

			rvu-sso-tim@0 {
				num-rvu-vfs = <0x04>;
				num-msix-vec = <0x400>;
			};

			rvu-npa@0 {
				num-rvu-vfs = <0x08>;
				num-msix-vec = <0x80>;
				provision-mode = "AVAILABLE";
			};

			rvu-ipsec@0 {
				num-rvu-vfs = <0x08>;
				num-msix-vec = <0xd2>;
			};

			rvu-sdp@0 {
				num-rvu-vfs = <0x09>;
				num-msix-vec = <0xd2>;
				provision-mode = "AVAILABLE";
				pf-srn = <0x00>;
				num-rvu-pf-rings = <0x00>;
				num-sdp-pfs = <0x01>;
				num-sdp-vfs = <0x08>;
				num-sdp-pf-rings = <0x08>;
				num-sdp-vf-rings = <0x08>;
			};

			rvu-cpt@0 {
				num-rvu-vfs = <0x40>;
				num-msix-vec = <0xc3>;
			};
		};

		pci@878030000000 {
			compatible = "pci-host-ecam-generic";
			device_type = "pci";
			msi-parent = <0x18 0x10080>;
			msi-map = <0x00 0x18 0x30000 0x10000>;
			bus-range = <0x00 0xff>;
			#size-cells = <0x02>;
			#address-cells = <0x03>;
			#stream-id-cells = <0x01>;
			dma-coherent;
			linux,pci-domain = <0x03>;
			iommu-map = <0x00 0x1a 0x30000 0x10000>;
			reg = <0x8780 0x30000000 0x00 0x10000000>;
			ranges = <0x1000000 0x00 0x00 0x8860 0x00 0x00 0x100000 0x3000000 0x00 0x1000000 0x8820 0x1000000 0x0f 0xff000000 0x43000000 0x10 0x00 0x8840 0x00 0x10 0x00 0x3000000 0x8e0e 0x00 0x8e0e 0x00 0x00 0x100000>;
			#interrupt-cells = <0x01>;
			interrupt-map-mask = <0x00 0x00 0x00 0x07>;
			interrupt-map = <0x00 0x00 0x00 0x01 0x01 0x00 0x00 0x00 0x09 0x04 0x00 0x00 0x00 0x02 0x01 0x00 0x00 0x00 0x0a 0x04 0x00 0x00 0x00 0x03 0x01 0x00 0x00 0x00 0x0b 0x04 0x00 0x00 0x00 0x04 0x01 0x00 0x00 0x00 0x0c 0x04>;
			phandle = <0x8a>;
		};

		pci@878040000000 {
			compatible = "pci-host-ecam-generic";
			device_type = "pci";
			msi-parent = <0x18 0x10088>;
			msi-map = <0x00 0x18 0x40000 0x10000>;
			bus-range = <0x00 0xff>;
			#size-cells = <0x02>;
			#address-cells = <0x03>;
			#stream-id-cells = <0x01>;
			dma-coherent;
			linux,pci-domain = <0x04>;
			iommu-map = <0x00 0x1a 0x40000 0x10000>;
			reg = <0x8780 0x40000000 0x00 0x10000000>;
			ranges = <0x1000000 0x00 0x00 0x88e0 0x00 0x00 0x100000 0x3000000 0x00 0x1000000 0x88a0 0x1000000 0x0f 0xff000000 0x43000000 0x10 0x00 0x88c0 0x00 0x10 0x00 0x3000000 0x8e1e 0x00 0x8e1e 0x00 0x00 0x100000>;
			#interrupt-cells = <0x01>;
			interrupt-map-mask = <0x00 0x00 0x00 0x07>;
			interrupt-map = <0x00 0x00 0x00 0x01 0x01 0x00 0x00 0x00 0x0d 0x04 0x00 0x00 0x00 0x02 0x01 0x00 0x00 0x00 0x0e 0x04 0x00 0x00 0x00 0x03 0x01 0x00 0x00 0x00 0x0f 0x04 0x00 0x00 0x00 0x04 0x01 0x00 0x00 0x00 0x10 0x04>;
			phandle = <0x8b>;
		};

		pci@878050000000 {
			compatible = "pci-host-ecam-generic";
			device_type = "pci";
			msi-parent = <0x18 0x10090>;
			msi-map = <0x00 0x18 0x50000 0x10000>;
			bus-range = <0x00 0xff>;
			#size-cells = <0x02>;
			#address-cells = <0x03>;
			#stream-id-cells = <0x01>;
			dma-coherent;
			linux,pci-domain = <0x05>;
			iommu-map = <0x00 0x1a 0x50000 0x10000>;
			reg = <0x8780 0x50000000 0x00 0x10000000>;
			ranges = <0x1000000 0x00 0x00 0x8960 0x00 0x00 0x100000 0x3000000 0x00 0x1000000 0x8920 0x1000000 0x0f 0xff000000 0x43000000 0x10 0x00 0x8940 0x00 0x10 0x00 0x3000000 0x8e2e 0x00 0x8e2e 0x00 0x00 0x100000>;
			#interrupt-cells = <0x01>;
			interrupt-map-mask = <0x00 0x00 0x00 0x07>;
			interrupt-map = <0x00 0x00 0x00 0x01 0x01 0x00 0x00 0x00 0x11 0x04 0x00 0x00 0x00 0x02 0x01 0x00 0x00 0x00 0x12 0x04 0x00 0x00 0x00 0x03 0x01 0x00 0x00 0x00 0x13 0x04 0x00 0x00 0x00 0x04 0x01 0x00 0x00 0x00 0x14 0x04>;
			phandle = <0x8c>;
		};

		pci@878060000000 {
			compatible = "pci-host-ecam-generic";
			device_type = "pci";
			msi-parent = <0x18 0x10098>;
			msi-map = <0x00 0x18 0x60000 0x10000>;
			bus-range = <0x00 0xff>;
			#size-cells = <0x02>;
			#address-cells = <0x03>;
			#stream-id-cells = <0x01>;
			dma-coherent;
			linux,pci-domain = <0x06>;
			iommu-map = <0x00 0x1a 0x60000 0x10000>;
			reg = <0x8780 0x60000000 0x00 0x10000000>;
			ranges = <0x1000000 0x00 0x00 0x89e0 0x00 0x00 0x100000 0x3000000 0x00 0x1000000 0x89a0 0x1000000 0x0f 0xff000000 0x43000000 0x10 0x00 0x89c0 0x00 0x10 0x00 0x3000000 0x8e3e 0x00 0x8e3e 0x00 0x00 0x100000>;
			#interrupt-cells = <0x01>;
			interrupt-map-mask = <0x00 0x00 0x00 0x07>;
			interrupt-map = <0x00 0x00 0x00 0x01 0x01 0x00 0x00 0x00 0x15 0x04 0x00 0x00 0x00 0x02 0x01 0x00 0x00 0x00 0x16 0x04 0x00 0x00 0x00 0x03 0x01 0x00 0x00 0x00 0x17 0x04 0x00 0x00 0x00 0x04 0x01 0x00 0x00 0x00 0x18 0x04>;
			phandle = <0x8d>;
		};

		pci@878070000000 {
			compatible = "pci-host-ecam-generic";
			device_type = "pci";
			msi-parent = <0x18 0x100a0>;
			msi-map = <0x00 0x18 0x70000 0x10000>;
			bus-range = <0x00 0xff>;
			#size-cells = <0x02>;
			#address-cells = <0x03>;
			#stream-id-cells = <0x01>;
			dma-coherent;
			linux,pci-domain = <0x07>;
			iommu-map = <0x00 0x1a 0x70000 0x10000>;
			reg = <0x8780 0x70000000 0x00 0x10000000>;
			ranges = <0x1000000 0x00 0x00 0x8a60 0x00 0x00 0x100000 0x3000000 0x00 0x1000000 0x8a20 0x1000000 0x0f 0xff000000 0x43000000 0x10 0x00 0x8a40 0x00 0x10 0x00 0x3000000 0x8e4e 0x00 0x8e4e 0x00 0x00 0x100000>;
			#interrupt-cells = <0x01>;
			interrupt-map-mask = <0x00 0x00 0x00 0x07>;
			interrupt-map = <0x00 0x00 0x00 0x01 0x01 0x00 0x00 0x00 0x19 0x04 0x00 0x00 0x00 0x02 0x01 0x00 0x00 0x00 0x1a 0x04 0x00 0x00 0x00 0x03 0x01 0x00 0x00 0x00 0x1b 0x04 0x00 0x00 0x00 0x04 0x01 0x00 0x00 0x00 0x1c 0x04>;
			phandle = <0x8e>;
		};

		pci@878080000000 {
			compatible = "pci-host-ecam-generic";
			device_type = "pci";
			msi-parent = <0x18 0x100a8>;
			msi-map = <0x00 0x18 0x80000 0x10000>;
			bus-range = <0x00 0xff>;
			#size-cells = <0x02>;
			#address-cells = <0x03>;
			#stream-id-cells = <0x01>;
			dma-coherent;
			linux,pci-domain = <0x08>;
			iommu-map = <0x00 0x1a 0x80000 0x10000>;
			reg = <0x8780 0x80000000 0x00 0x10000000>;
			ranges = <0x1000000 0x00 0x00 0x8ae0 0x00 0x00 0x100000 0x3000000 0x00 0x1000000 0x8aa0 0x1000000 0x0f 0xff000000 0x43000000 0x10 0x00 0x8ac0 0x00 0x10 0x00 0x3000000 0x8e5e 0x00 0x8e5e 0x00 0x00 0x100000>;
			#interrupt-cells = <0x01>;
			interrupt-map-mask = <0x00 0x00 0x00 0x07>;
			interrupt-map = <0x00 0x00 0x00 0x01 0x01 0x00 0x00 0x00 0x1d 0x04 0x00 0x00 0x00 0x02 0x01 0x00 0x00 0x00 0x1e 0x04 0x00 0x00 0x00 0x03 0x01 0x00 0x00 0x00 0x1f 0x04 0x00 0x00 0x00 0x04 0x01 0x00 0x00 0x00 0x20 0x04>;
			phandle = <0x8f>;
		};

		pcie-ep@0 {
			compatible = "marvell,cn10k-pem-ep";
			reg = <0x8e00 0x00 0x10 0x00>;
			interrupts = <0x00 0x5b 0x01 0x00 0x1f8 0x01 0x00 0x1f9 0x01 0x00 0x1fa 0x01 0x00 0x1fb 0x01 0x00 0x1fc 0x01 0x00 0x1fd 0x01 0x00 0x1fe 0x01 0x00 0x1ff 0x01>;
		};

		sdei-ghes {
			compatible = "marvell,sdei-ghes";
			#address-cells = <0x02>;
			#size-cells = <0x01>;
			memory-region = <0x21>;
			ranges = <0x00 0x00 0x07 0xfaf00000 0x400 0x00 0x400 0x07 0xfaf00400 0x6c00 0x00 0x7000 0x07 0xfaf07000 0xf9000>;

			mdc {
				reg = <0x00 0x00 0x08 0x00 0x400 0xfa 0x00 0x7000 0x1600>;
				event-id = <0x40000000>;
			};

			dss {
				reg = <0x00 0x08 0x08 0x00 0x500 0xfa 0x00 0x8600 0x1600>;
				event-id = <0x40000001>;
			};

			tad {
				reg = <0x00 0x10 0x08 0x00 0x600 0xfa 0x00 0x9c00 0x1600>;
				event-id = <0x40000002>;
			};

			core0 {
				reg = <0x00 0x18 0x08 0x00 0x700 0xfa 0x00 0xb200 0x1600>;
				event-id = <0x40000003>;
			};

			core1 {
				reg = <0x00 0x20 0x08 0x00 0x800 0xfa 0x00 0xc800 0x1600>;
				event-id = <0x40000004>;
			};

			core2 {
				reg = <0x00 0x28 0x08 0x00 0x900 0xfa 0x00 0xde00 0x1600>;
				event-id = <0x40000005>;
			};

			core3 {
				reg = <0x00 0x30 0x08 0x00 0xa00 0xfa 0x00 0xf400 0x1600>;
				event-id = <0x40000006>;
			};

			core4 {
				reg = <0x00 0x38 0x08 0x00 0xb00 0xfa 0x00 0x10a00 0x1600>;
				event-id = <0x40000007>;
			};

			core5 {
				reg = <0x00 0x40 0x08 0x00 0xc00 0xfa 0x00 0x12000 0x1600>;
				event-id = <0x40000008>;
			};

			core6 {
				reg = <0x00 0x48 0x08 0x00 0xd00 0xfa 0x00 0x13600 0x1600>;
				event-id = <0x40000009>;
			};

			core7 {
				reg = <0x00 0x50 0x08 0x00 0xe00 0xfa 0x00 0x14c00 0x1600>;
				event-id = <0x4000000a>;
			};

			gic {
				reg = <0x00 0x58 0x08 0x00 0xf00 0xfa 0x00 0x16200 0x1600>;
				event-id = <0x4000001b>;
			};
		};

		serial@87e029000000 {
			compatible = "arm,pl011", "arm,primecell";
			reg = <0x87e0 0x29000000 0x00 0x1000>;
			interrupts = <0x00 0x01 0x04>;
			clocks = <0x14>;
			clock-names = "apb_pclk";
			skip-init;
			phandle = <0x90>;
		};

		serial@87e02a000000 {
			compatible = "arm,pl011", "arm,primecell";
			reg = <0x87e0 0x2a000000 0x00 0x1000>;
			interrupts = <0x00 0x02 0x04>;
			clocks = <0x14>;
			clock-names = "apb_pclk";
			skip-init;
			phandle = <0x91>;
		};

		serial@87e02b000000 {
			compatible = "arm,pl011", "arm,primecell";
			reg = <0x87e0 0x2b000000 0x00 0x1000>;
			interrupts = <0x00 0x03 0x04>;
			clocks = <0x14>;
			clock-names = "apb_pclk";
			skip-init;
			phandle = <0x92>;
		};

		serial@87e02c000000 {
			compatible = "arm,pl011", "arm,primecell";
			reg = <0x87e0 0x2c000000 0x00 0x1000>;
			interrupts = <0x00 0x04 0x04>;
			clocks = <0x14>;
			clock-names = "apb_pclk";
			skip-init;
			phandle = <0x93>;
		};

		serial@87e02d000000 {
			compatible = "arm,pl011", "arm,primecell";
			reg = <0x87e0 0x2d000000 0x00 0x1000>;
			interrupts = <0x00 0x05 0x04>;
			clocks = <0x14>;
			clock-names = "apb_pclk";
			skip-init;
			phandle = <0x94>;
		};

		serial@87e02e000000 {
			compatible = "arm,pl011", "arm,primecell";
			reg = <0x87e0 0x2e000000 0x00 0x1000>;
			interrupts = <0x00 0x06 0x04>;
			clocks = <0x14>;
			clock-names = "apb_pclk";
			skip-init;
			phandle = <0x95>;
		};

		serial@87e02f000000 {
			compatible = "arm,pl011", "arm,primecell";
			reg = <0x87e0 0x2f000000 0x00 0x1000>;
			interrupts = <0x00 0x07 0x04>;
			clocks = <0x14>;
			clock-names = "apb_pclk";
			skip-init;
			phandle = <0x96>;
		};

		pci@878010000000 {
			compatible = "pci-host-ecam-generic";
			device_type = "pci";
			msi-map = <0x00 0x18 0x10000 0x10000>;
			bus-range = <0x00 0xff>;
			#size-cells = <0x02>;
			#address-cells = <0x03>;
			dma-coherent;
			linux,pci-domain = <0x01>;
			reg = <0x8780 0x10000000 0x00 0x10000000>;
			iommu-map = <0x00 0x1a 0x10000 0x10000>;
			ranges = <0x3000000 0x8680 0x00 0x8680 0x00 0x20 0x00 0x3000000 0x87e0 0xfe9c0000 0x87e0 0xfe9c0000 0x00 0x10000 0x3000000 0x8e00 0x00 0x8e00 0x00 0x00 0x40000000 0x3000000 0x8e10 0x00 0x8e10 0x00 0x00 0x40000000 0x3000000 0x8e20 0x00 0x8e20 0x00 0x00 0x40000000 0x3000000 0x8e30 0x00 0x8e30 0x00 0x00 0x40000000 0x3000000 0x8e40 0x00 0x8e40 0x00 0x00 0x40000000 0x3000000 0x8e50 0x00 0x8e50 0x00 0x00 0x40000000 0x3000000 0x8e0f 0x00 0x8e0f 0x00 0x00 0x100000 0x3000000 0x8e1f 0x00 0x8e1f 0x00 0x00 0x100000 0x3000000 0x8e2f 0x00 0x8e2f 0x00 0x00 0x100000 0x3000000 0x8e3f 0x00 0x8e3f 0x00 0x00 0x100000 0x3000000 0x8e4f 0x00 0x8e4f 0x00 0x00 0x100000 0x3000000 0x8e5f 0x00 0x8e5f 0x00 0x00 0x100000>;
			phandle = <0x97>;
		};

		ete0 {
			compatible = "arm,embedded-trace-extension";
			clocks = <0x17>;
			clock-names = "apb_pclk";
			cpu = <0x02>;
			metadata-region = <0x00 0x00 0x00 0x00>;
			phandle = <0x26>;

			out-ports {

				port {

					endpoint {
						remote-endpoint = <0x22>;
						phandle = <0x24>;
					};
				};
			};
		};

		etf0@87a004010000 {
			compatible = "arm,coresight-tmc", "arm,primecell";
			reg = <0x87a0 0x4010000 0x00 0x1000>;
			clocks = <0x17>;
			clock-names = "apb_pclk";
			cpu = <0x02>;
			memory-region = <0x23>;
			metadata-region = <0x00 0x00 0x00 0x00>;
			phandle = <0x27>;

			in-ports {

				port {

					endpoint {
						slave-mode;
						remote-endpoint = <0x24>;
						phandle = <0x22>;
					};
				};
			};

			out-ports {

				port {

					endpoint {
						remote-endpoint = <0x25>;
						phandle = <0x53>;
					};
				};
			};
		};

		ap_cti0@87a080010000 {
			compatible = "arm,coresight-cti-v8-arch", "arm,coresight-cti", "arm,primecell";
			reg = <0x87a0 0x80010000 0x00 0x1000>;
			clocks = <0x17>;
			clock-names = "apb_pclk";
			cpu = <0x02>;
			arm,cs-dev-assoc = <0x26>;
		};

		etf_cti0@87a004020000 {
			compatible = "arm,coresight-cti", "arm,primecell";
			reg = <0x87a0 0x4020000 0x00 0x1000>;
			clocks = <0x17>;
			clock-names = "apb_pclk";
			#address-cells = <0x01>;
			#size-cells = <0x00>;

			trig-conns@0 {
				reg = <0x00>;
				arm,trig-in-sigs = <0x00 0x01 0x02>;
				arm,trig-in-types = <0x0e 0x0d 0x0c>;
				arm,trig-out-sigs = <0x00 0x01>;
				arm,trig-out-types = <0x10 0x0f>;
				arm,cs-dev-assoc = <0x27>;
			};
		};

		ete1 {
			compatible = "arm,embedded-trace-extension";
			clocks = <0x17>;
			clock-names = "apb_pclk";
			cpu = <0x03>;
			metadata-region = <0x00 0x00 0x00 0x00>;
			phandle = <0x2c>;

			out-ports {

				port {

					endpoint {
						remote-endpoint = <0x28>;
						phandle = <0x2a>;
					};
				};
			};
		};

		etf1@87a004110000 {
			compatible = "arm,coresight-tmc", "arm,primecell";
			reg = <0x87a0 0x4110000 0x00 0x1000>;
			clocks = <0x17>;
			clock-names = "apb_pclk";
			cpu = <0x03>;
			memory-region = <0x29>;
			metadata-region = <0x00 0x00 0x00 0x00>;
			phandle = <0x2d>;

			in-ports {

				port {

					endpoint {
						slave-mode;
						remote-endpoint = <0x2a>;
						phandle = <0x28>;
					};
				};
			};

			out-ports {

				port {

					endpoint {
						remote-endpoint = <0x2b>;
						phandle = <0x54>;
					};
				};
			};
		};

		ap_cti1@87a082010000 {
			compatible = "arm,coresight-cti-v8-arch", "arm,coresight-cti", "arm,primecell";
			reg = <0x87a0 0x82010000 0x00 0x1000>;
			clocks = <0x17>;
			clock-names = "apb_pclk";
			cpu = <0x03>;
			arm,cs-dev-assoc = <0x2c>;
		};

		etf_cti1@87a004120000 {
			compatible = "arm,coresight-cti", "arm,primecell";
			reg = <0x87a0 0x4120000 0x00 0x1000>;
			clocks = <0x17>;
			clock-names = "apb_pclk";
			#address-cells = <0x01>;
			#size-cells = <0x00>;

			trig-conns@0 {
				reg = <0x00>;
				arm,trig-in-sigs = <0x00 0x01 0x02>;
				arm,trig-in-types = <0x0e 0x0d 0x0c>;
				arm,trig-out-sigs = <0x00 0x01>;
				arm,trig-out-types = <0x10 0x0f>;
				arm,cs-dev-assoc = <0x2d>;
			};
		};

		ete2 {
			compatible = "arm,embedded-trace-extension";
			clocks = <0x17>;
			clock-names = "apb_pclk";
			cpu = <0x04>;
			metadata-region = <0x00 0x00 0x00 0x00>;
			phandle = <0x32>;

			out-ports {

				port {

					endpoint {
						remote-endpoint = <0x2e>;
						phandle = <0x30>;
					};
				};
			};
		};

		etf2@87a004210000 {
			compatible = "arm,coresight-tmc", "arm,primecell";
			reg = <0x87a0 0x4210000 0x00 0x1000>;
			clocks = <0x17>;
			clock-names = "apb_pclk";
			cpu = <0x04>;
			memory-region = <0x2f>;
			metadata-region = <0x00 0x00 0x00 0x00>;
			phandle = <0x33>;

			in-ports {

				port {

					endpoint {
						slave-mode;
						remote-endpoint = <0x30>;
						phandle = <0x2e>;
					};
				};
			};

			out-ports {

				port {

					endpoint {
						remote-endpoint = <0x31>;
						phandle = <0x55>;
					};
				};
			};
		};

		ap_cti2@87a084010000 {
			compatible = "arm,coresight-cti-v8-arch", "arm,coresight-cti", "arm,primecell";
			reg = <0x87a0 0x84010000 0x00 0x1000>;
			clocks = <0x17>;
			clock-names = "apb_pclk";
			cpu = <0x04>;
			arm,cs-dev-assoc = <0x32>;
		};

		etf_cti2@87a004220000 {
			compatible = "arm,coresight-cti", "arm,primecell";
			reg = <0x87a0 0x4220000 0x00 0x1000>;
			clocks = <0x17>;
			clock-names = "apb_pclk";
			#address-cells = <0x01>;
			#size-cells = <0x00>;

			trig-conns@0 {
				reg = <0x00>;
				arm,trig-in-sigs = <0x00 0x01 0x02>;
				arm,trig-in-types = <0x0e 0x0d 0x0c>;
				arm,trig-out-sigs = <0x00 0x01>;
				arm,trig-out-types = <0x10 0x0f>;
				arm,cs-dev-assoc = <0x33>;
			};
		};

		ete3 {
			compatible = "arm,embedded-trace-extension";
			clocks = <0x17>;
			clock-names = "apb_pclk";
			cpu = <0x05>;
			metadata-region = <0x00 0x00 0x00 0x00>;
			phandle = <0x38>;

			out-ports {

				port {

					endpoint {
						remote-endpoint = <0x34>;
						phandle = <0x36>;
					};
				};
			};
		};

		etf3@87a004310000 {
			compatible = "arm,coresight-tmc", "arm,primecell";
			reg = <0x87a0 0x4310000 0x00 0x1000>;
			clocks = <0x17>;
			clock-names = "apb_pclk";
			cpu = <0x05>;
			memory-region = <0x35>;
			metadata-region = <0x00 0x00 0x00 0x00>;
			phandle = <0x39>;

			in-ports {

				port {

					endpoint {
						slave-mode;
						remote-endpoint = <0x36>;
						phandle = <0x34>;
					};
				};
			};

			out-ports {

				port {

					endpoint {
						remote-endpoint = <0x37>;
						phandle = <0x56>;
					};
				};
			};
		};

		ap_cti3@87a086010000 {
			compatible = "arm,coresight-cti-v8-arch", "arm,coresight-cti", "arm,primecell";
			reg = <0x87a0 0x86010000 0x00 0x1000>;
			clocks = <0x17>;
			clock-names = "apb_pclk";
			cpu = <0x05>;
			arm,cs-dev-assoc = <0x38>;
		};

		etf_cti3@87a004320000 {
			compatible = "arm,coresight-cti", "arm,primecell";
			reg = <0x87a0 0x4320000 0x00 0x1000>;
			clocks = <0x17>;
			clock-names = "apb_pclk";
			#address-cells = <0x01>;
			#size-cells = <0x00>;

			trig-conns@0 {
				reg = <0x00>;
				arm,trig-in-sigs = <0x00 0x01 0x02>;
				arm,trig-in-types = <0x0e 0x0d 0x0c>;
				arm,trig-out-sigs = <0x00 0x01>;
				arm,trig-out-types = <0x10 0x0f>;
				arm,cs-dev-assoc = <0x39>;
			};
		};

		ete4 {
			compatible = "arm,embedded-trace-extension";
			clocks = <0x17>;
			clock-names = "apb_pclk";
			cpu = <0x06>;
			metadata-region = <0x00 0x00 0x00 0x00>;
			phandle = <0x3e>;

			out-ports {

				port {

					endpoint {
						remote-endpoint = <0x3a>;
						phandle = <0x3c>;
					};
				};
			};
		};

		etf4@87a004410000 {
			compatible = "arm,coresight-tmc", "arm,primecell";
			reg = <0x87a0 0x4410000 0x00 0x1000>;
			clocks = <0x17>;
			clock-names = "apb_pclk";
			cpu = <0x06>;
			memory-region = <0x3b>;
			metadata-region = <0x00 0x00 0x00 0x00>;
			phandle = <0x3f>;

			in-ports {

				port {

					endpoint {
						slave-mode;
						remote-endpoint = <0x3c>;
						phandle = <0x3a>;
					};
				};
			};

			out-ports {

				port {

					endpoint {
						remote-endpoint = <0x3d>;
						phandle = <0x57>;
					};
				};
			};
		};

		ap_cti4@87a088010000 {
			compatible = "arm,coresight-cti-v8-arch", "arm,coresight-cti", "arm,primecell";
			reg = <0x87a0 0x88010000 0x00 0x1000>;
			clocks = <0x17>;
			clock-names = "apb_pclk";
			cpu = <0x06>;
			arm,cs-dev-assoc = <0x3e>;
		};

		etf_cti4@87a004420000 {
			compatible = "arm,coresight-cti", "arm,primecell";
			reg = <0x87a0 0x4420000 0x00 0x1000>;
			clocks = <0x17>;
			clock-names = "apb_pclk";
			#address-cells = <0x01>;
			#size-cells = <0x00>;

			trig-conns@0 {
				reg = <0x00>;
				arm,trig-in-sigs = <0x00 0x01 0x02>;
				arm,trig-in-types = <0x0e 0x0d 0x0c>;
				arm,trig-out-sigs = <0x00 0x01>;
				arm,trig-out-types = <0x10 0x0f>;
				arm,cs-dev-assoc = <0x3f>;
			};
		};

		ete5 {
			compatible = "arm,embedded-trace-extension";
			clocks = <0x17>;
			clock-names = "apb_pclk";
			cpu = <0x07>;
			metadata-region = <0x00 0x00 0x00 0x00>;
			phandle = <0x44>;

			out-ports {

				port {

					endpoint {
						remote-endpoint = <0x40>;
						phandle = <0x42>;
					};
				};
			};
		};

		etf5@87a004510000 {
			compatible = "arm,coresight-tmc", "arm,primecell";
			reg = <0x87a0 0x4510000 0x00 0x1000>;
			clocks = <0x17>;
			clock-names = "apb_pclk";
			cpu = <0x07>;
			memory-region = <0x41>;
			metadata-region = <0x00 0x00 0x00 0x00>;
			phandle = <0x45>;

			in-ports {

				port {

					endpoint {
						slave-mode;
						remote-endpoint = <0x42>;
						phandle = <0x40>;
					};
				};
			};

			out-ports {

				port {

					endpoint {
						remote-endpoint = <0x43>;
						phandle = <0x58>;
					};
				};
			};
		};

		ap_cti5@87a08a010000 {
			compatible = "arm,coresight-cti-v8-arch", "arm,coresight-cti", "arm,primecell";
			reg = <0x87a0 0x8a010000 0x00 0x1000>;
			clocks = <0x17>;
			clock-names = "apb_pclk";
			cpu = <0x07>;
			arm,cs-dev-assoc = <0x44>;
		};

		etf_cti5@87a004520000 {
			compatible = "arm,coresight-cti", "arm,primecell";
			reg = <0x87a0 0x4520000 0x00 0x1000>;
			clocks = <0x17>;
			clock-names = "apb_pclk";
			#address-cells = <0x01>;
			#size-cells = <0x00>;

			trig-conns@0 {
				reg = <0x00>;
				arm,trig-in-sigs = <0x00 0x01 0x02>;
				arm,trig-in-types = <0x0e 0x0d 0x0c>;
				arm,trig-out-sigs = <0x00 0x01>;
				arm,trig-out-types = <0x10 0x0f>;
				arm,cs-dev-assoc = <0x45>;
			};
		};

		ete6 {
			compatible = "arm,embedded-trace-extension";
			clocks = <0x17>;
			clock-names = "apb_pclk";
			cpu = <0x08>;
			metadata-region = <0x00 0x00 0x00 0x00>;
			phandle = <0x4a>;

			out-ports {

				port {

					endpoint {
						remote-endpoint = <0x46>;
						phandle = <0x48>;
					};
				};
			};
		};

		etf6@87a004610000 {
			compatible = "arm,coresight-tmc", "arm,primecell";
			reg = <0x87a0 0x4610000 0x00 0x1000>;
			clocks = <0x17>;
			clock-names = "apb_pclk";
			cpu = <0x08>;
			memory-region = <0x47>;
			metadata-region = <0x00 0x00 0x00 0x00>;
			phandle = <0x4b>;

			in-ports {

				port {

					endpoint {
						slave-mode;
						remote-endpoint = <0x48>;
						phandle = <0x46>;
					};
				};
			};

			out-ports {

				port {

					endpoint {
						remote-endpoint = <0x49>;
						phandle = <0x59>;
					};
				};
			};
		};

		ap_cti6@87a08c010000 {
			compatible = "arm,coresight-cti-v8-arch", "arm,coresight-cti", "arm,primecell";
			reg = <0x87a0 0x8c010000 0x00 0x1000>;
			clocks = <0x17>;
			clock-names = "apb_pclk";
			cpu = <0x08>;
			arm,cs-dev-assoc = <0x4a>;
		};

		etf_cti6@87a004620000 {
			compatible = "arm,coresight-cti", "arm,primecell";
			reg = <0x87a0 0x4620000 0x00 0x1000>;
			clocks = <0x17>;
			clock-names = "apb_pclk";
			#address-cells = <0x01>;
			#size-cells = <0x00>;

			trig-conns@0 {
				reg = <0x00>;
				arm,trig-in-sigs = <0x00 0x01 0x02>;
				arm,trig-in-types = <0x0e 0x0d 0x0c>;
				arm,trig-out-sigs = <0x00 0x01>;
				arm,trig-out-types = <0x10 0x0f>;
				arm,cs-dev-assoc = <0x4b>;
			};
		};

		ete7 {
			compatible = "arm,embedded-trace-extension";
			clocks = <0x17>;
			clock-names = "apb_pclk";
			cpu = <0x09>;
			metadata-region = <0x00 0x00 0x00 0x00>;
			phandle = <0x50>;

			out-ports {

				port {

					endpoint {
						remote-endpoint = <0x4c>;
						phandle = <0x4e>;
					};
				};
			};
		};

		etf7@87a004710000 {
			compatible = "arm,coresight-tmc", "arm,primecell";
			reg = <0x87a0 0x4710000 0x00 0x1000>;
			clocks = <0x17>;
			clock-names = "apb_pclk";
			cpu = <0x09>;
			memory-region = <0x4d>;
			metadata-region = <0x00 0x00 0x00 0x00>;
			phandle = <0x51>;

			in-ports {

				port {

					endpoint {
						slave-mode;
						remote-endpoint = <0x4e>;
						phandle = <0x4c>;
					};
				};
			};

			out-ports {

				port {

					endpoint {
						remote-endpoint = <0x4f>;
						phandle = <0x5a>;
					};
				};
			};
		};

		ap_cti7@87a08e010000 {
			compatible = "arm,coresight-cti-v8-arch", "arm,coresight-cti", "arm,primecell";
			reg = <0x87a0 0x8e010000 0x00 0x1000>;
			clocks = <0x17>;
			clock-names = "apb_pclk";
			cpu = <0x09>;
			arm,cs-dev-assoc = <0x50>;
		};

		etf_cti7@87a004720000 {
			compatible = "arm,coresight-cti", "arm,primecell";
			reg = <0x87a0 0x4720000 0x00 0x1000>;
			clocks = <0x17>;
			clock-names = "apb_pclk";
			#address-cells = <0x01>;
			#size-cells = <0x00>;

			trig-conns@0 {
				reg = <0x00>;
				arm,trig-in-sigs = <0x00 0x01 0x02>;
				arm,trig-in-types = <0x0e 0x0d 0x0c>;
				arm,trig-out-sigs = <0x00 0x01>;
				arm,trig-out-types = <0x10 0x0f>;
				arm,cs-dev-assoc = <0x51>;
			};
		};

		st_funnel {
			compatible = "arm,coresight-static-funnel";
			clocks = <0x17>;
			clock-names = "apb_pclk";

			out-ports {

				port {

					endpoint {
						remote-endpoint = <0x52>;
						phandle = <0x5b>;
					};
				};
			};

			in-ports {
				#address-cells = <0x01>;
				#size-cells = <0x00>;

				port@0 {
					reg = <0x00>;

					endpoint {
						remote-endpoint = <0x53>;
						phandle = <0x25>;
					};
				};

				port@1 {
					reg = <0x01>;

					endpoint {
						remote-endpoint = <0x54>;
						phandle = <0x2b>;
					};
				};

				port@2 {
					reg = <0x02>;

					endpoint {
						remote-endpoint = <0x55>;
						phandle = <0x31>;
					};
				};

				port@3 {
					reg = <0x03>;

					endpoint {
						remote-endpoint = <0x56>;
						phandle = <0x37>;
					};
				};

				port@4 {
					reg = <0x04>;

					endpoint {
						remote-endpoint = <0x57>;
						phandle = <0x3d>;
					};
				};

				port@5 {
					reg = <0x05>;

					endpoint {
						remote-endpoint = <0x58>;
						phandle = <0x43>;
					};
				};

				port@6 {
					reg = <0x06>;

					endpoint {
						remote-endpoint = <0x59>;
						phandle = <0x49>;
					};
				};

				port@7 {
					reg = <0x07>;

					endpoint {
						remote-endpoint = <0x5a>;
						phandle = <0x4f>;
					};
				};
			};
		};

		sh_etf@87a100050000 {
			compatible = "arm,coresight-tmc", "arm,primecell";
			reg = <0x87a1 0x50000 0x00 0x1000>;
			clocks = <0x17>;
			clock-names = "apb_pclk";

			in-ports {

				port {

					endpoint {
						remote-endpoint = <0x5b>;
						phandle = <0x52>;
					};
				};
			};

			out-ports {

				port {

					endpoint {
						remote-endpoint = <0x5c>;
						phandle = <0x5e>;
					};
				};
			};
		};

		sh_etr@87a100060000 {
			compatible = "arm,coresight-tmc", "arm,primecell";
			reg = <0x87a1 0x60000 0x00 0x1000>;
			clocks = <0x17>;
			clock-names = "apb_pclk";
			iommus = <0x1a 0x50>;
			arm,max-burst-size = <0x07>;
			memory-region = <0x5d>;
			metadata-region = <0x00 0x00 0x00 0x00>;
			phandle = <0x5f>;

			in-ports {

				port {

					endpoint {
						remote-endpoint = <0x5e>;
						phandle = <0x5c>;
					};
				};
			};
		};

		sh_cti@87a100030000 {
			compatible = "arm,coresight-cti", "arm,primecell";
			reg = <0x87a1 0x30000 0x00 0x1000>;
			clocks = <0x17>;
			clock-names = "apb_pclk";
			#address-cells = <0x01>;
			#size-cells = <0x00>;

			trig-conns@0 {
				reg = <0x00>;
				arm,trig-in-sigs = <0x00 0x01 0x02 0x03 0x04 0x05>;
				arm,trig-in-types = <0x0e 0x0e 0x0d 0x0d 0x0c 0x0c>;
				arm,trig-out-sigs = <0x00 0x01 0x02 0x03>;
				arm,trig-out-types = <0x0f 0x0f 0x10 0x10>;
				arm,cs-dev-assoc = <0x5f>;
			};
		};

		pmpcsr0@87a081020000 {
			compatible = "arm,primecell";
			reg = <0x87a0 0x81020000 0x00 0x1000>;
			clocks = <0x17>;
			clock-names = "apb_pclk";
			cpu = <0x02>;
		};

		pmpcsr1@87a083020000 {
			compatible = "arm,primecell";
			reg = <0x87a0 0x83020000 0x00 0x1000>;
			clocks = <0x17>;
			clock-names = "apb_pclk";
			cpu = <0x03>;
		};

		pmpcsr2@87a085020000 {
			compatible = "arm,primecell";
			reg = <0x87a0 0x85020000 0x00 0x1000>;
			clocks = <0x17>;
			clock-names = "apb_pclk";
			cpu = <0x04>;
		};

		pmpcsr3@87a087020000 {
			compatible = "arm,primecell";
			reg = <0x87a0 0x87020000 0x00 0x1000>;
			clocks = <0x17>;
			clock-names = "apb_pclk";
			cpu = <0x05>;
		};

		pmpcsr4@87a089020000 {
			compatible = "arm,primecell";
			reg = <0x87a0 0x89020000 0x00 0x1000>;
			clocks = <0x17>;
			clock-names = "apb_pclk";
			cpu = <0x06>;
		};

		pmpcsr5@87a08b020000 {
			compatible = "arm,primecell";
			reg = <0x87a0 0x8b020000 0x00 0x1000>;
			clocks = <0x17>;
			clock-names = "apb_pclk";
			cpu = <0x07>;
		};

		pmpcsr6@87a08d020000 {
			compatible = "arm,primecell";
			reg = <0x87a0 0x8d020000 0x00 0x1000>;
			clocks = <0x17>;
			clock-names = "apb_pclk";
			cpu = <0x08>;
		};

		pmpcsr7@87a08f020000 {
			compatible = "arm,primecell";
			reg = <0x87a0 0x8f020000 0x00 0x1000>;
			clocks = <0x17>;
			clock-names = "apb_pclk";
			cpu = <0x09>;
		};

		hdd_pwrctl-v3 {
			compatible = "ubnt, hdd-pwrctl-v3";

			hdd@5 {
				hdds-present = <0x1d7>;
				hdds-pwren = <0x1df>;
				pwroff-delay = <0x1f4>;
				hdds-fault-led = <0x1bf>;
				pwren-delay = <0x3e8>;
			};

			hdd@1 {
				hdds-present = <0x1d6>;
				hdds-pwren = <0x1de>;
				pwroff-delay = <0x1f4>;
				hdds-fault-led = <0x1be>;
				pwren-delay = <0x3e8>;
			};

			hdd@2 {
				hdds-present = <0x1d5>;
				hdds-pwren = <0x1dd>;
				pwroff-delay = <0x1f4>;
				hdds-fault-led = <0x1bd>;
				pwren-delay = <0x3e8>;
			};

			hdd@6 {
				hdds-present = <0x1d4>;
				hdds-pwren = <0x1dc>;
				pwroff-delay = <0x1f4>;
				hdds-fault-led = <0x1bc>;
				pwren-delay = <0x3e8>;
			};

			hdd@13 {
				hdds-present = <0x1d3>;
				hdds-pwren = <0x1db>;
				pwroff-delay = <0x1f4>;
				hdds-fault-led = <0x1bb>;
				pwren-delay = <0x3e8>;
			};

			hdd@9 {
				hdds-present = <0x1d2>;
				hdds-pwren = <0x1da>;
				pwroff-delay = <0x1f4>;
				hdds-fault-led = <0x1ba>;
				pwren-delay = <0x3e8>;
			};

			hdd@10 {
				hdds-present = <0x1d1>;
				hdds-pwren = <0x1d9>;
				pwroff-delay = <0x1f4>;
				hdds-fault-led = <0x1b9>;
				pwren-delay = <0x3e8>;
			};

			hdd@14 {
				hdds-present = <0x1d0>;
				hdds-pwren = <0x1d8>;
				pwroff-delay = <0x1f4>;
				hdds-fault-led = <0x1b8>;
				pwren-delay = <0x3e8>;
			};

			hdd@7 {
				hdds-present = <0x1c7>;
				hdds-pwren = <0x1cf>;
				pwroff-delay = <0x1f4>;
				hdds-fault-led = <0x1af>;
				pwren-delay = <0x3e8>;
			};

			hdd@3 {
				hdds-present = <0x1c6>;
				hdds-pwren = <0x1ce>;
				pwroff-delay = <0x1f4>;
				hdds-fault-led = <0x1ae>;
				pwren-delay = <0x3e8>;
			};

			hdd@4 {
				hdds-present = <0x1c5>;
				hdds-pwren = <0x1cd>;
				pwroff-delay = <0x1f4>;
				hdds-fault-led = <0x1ad>;
				pwren-delay = <0x3e8>;
			};

			hdd@8 {
				hdds-present = <0x1c4>;
				hdds-pwren = <0x1cc>;
				pwroff-delay = <0x1f4>;
				hdds-fault-led = <0x1ac>;
				pwren-delay = <0x3e8>;
			};

			hdd@15 {
				hdds-present = <0x1c3>;
				hdds-pwren = <0x1cb>;
				pwroff-delay = <0x1f4>;
				hdds-fault-led = <0x1ab>;
				pwren-delay = <0x3e8>;
			};

			hdd@11 {
				hdds-present = <0x1c2>;
				hdds-pwren = <0x1ca>;
				pwroff-delay = <0x1f4>;
				hdds-fault-led = <0x1aa>;
				pwren-delay = <0x3e8>;
			};

			hdd@12 {
				hdds-present = <0x1c1>;
				hdds-pwren = <0x1c9>;
				pwroff-delay = <0x1f4>;
				hdds-fault-led = <0x1a9>;
				pwren-delay = <0x3e8>;
			};

			hdd@16 {
				hdds-present = <0x1c0>;
				hdds-pwren = <0x1c8>;
				pwroff-delay = <0x1f4>;
				hdds-fault-led = <0x1a8>;
				pwren-delay = <0x3e8>;
			};
		};

		gpio_keys {
			compatible = "gpio-keys";

			reset_button {
				label = "Reset Button";
				linux,code = <0x198>;
				debounce-interval = <0xc8>;
				gpios = <0x88 0x07 0x01>;
			};
		};
	};

	chosen {
		stdout-path = "/soc@0/serial@87e028000000";
	};

	memory@0 {
		device_type = "memory";
		reg = <0x00 0x4000000 0x07 0xfc000000>;
		numa-node-id = <0x00>;
	};

	firmware {

		optee {
			compatible = "linaro,optee-tz";
			method = "smc";
			status = "okay";
		};

		scmi {
			compatible = "arm,scmi";
			mboxes = <0x60 0x00>;
			mbox-names = "scp_ap";
			shmem = <0x61>;
			#address-cells = <0x01>;
			#size-cells = <0x00>;

			protocol@13 {
				reg = <0x13>;
				#clock-cells = <0x01>;
				phandle = <0x0b>;
			};

			protocol@14 {
				reg = <0x14>;
				#clock-cells = <0x01>;
				phandle = <0x98>;
			};

			protocol@15 {
				reg = <0x15>;
				#thermal-sensor-cells = <0x01>;
				phandle = <0x99>;
			};
		};

		sdei {
			compatible = "arm,sdei-1.0";
			method = "smc";
		};
	};

	aliases {
		serial0 = "/soc@0/serial@87e028000000";
		serial1 = "/soc@0/serial@87e029000000";
		serial2 = "/soc@0/serial@87e02a000000";
		serial3 = "/soc@0/serial@87e02b000000";
		serial4 = "/soc@0/serial@87e02c000000";
		serial5 = "/soc@0/serial@87e02d000000";
		serial6 = "/soc@0/serial@87e02e000000";
		serial7 = "/soc@0/serial@87e02f000000";
		spi0 = "/soc@0/spi@804000000000";
		spi1 = "/soc@0/spi@805000000000";
		i2c0 = "/soc@0/pci@878000000000/mrml-bridge0@1,0/i2c@24,0";
		i2c1 = "/soc@0/pci@878000000000/mrml-bridge0@1,0/i2c@24,1";
		i2c2 = "/soc@0/pci@878000000000/mrml-bridge0@1,0/i2c@24,2";
		i2c3 = "/soc@0/pci@878000000000/mrml-bridge0@1,0/i2c@24,3";
		phandle = <0x9a>;
	};

	vqmmc_supply_1v8 {
		compatible = "regulator-fixed";
		regulator-name = "vqmmc_supply_1v8";
		regulator-min-microvolt = <0x1b7740>;
		regulator-max-microvolt = <0x1b7740>;
		enable-active-high;
		startup-delay-us = <0x0a>;
		phandle = <0x1c>;
	};

	mmc_supply_1v8 {
		compatible = "regulator-fixed";
		regulator-name = "mmc_supply_1v8";
		regulator-min-microvolt = <0x1b7740>;
		regulator-max-microvolt = <0x1b7740>;
		enable-active-high;
		phandle = <0x1b>;
	};

	__symbols__ {
		console_reserved = "/reserved-memory/pci-console-nexus";
		fwlogmem = "/reserved-memory/fwlogs@0";
		ghes_hest_reserved = "/reserved-memory/ghes-hest@0000000000000000";
		coresight_reserved = "/reserved-memory/coresight-presrv@0";
		etf0_trace = "/reserved-memory/etf0_trace@0";
		etf1_trace = "/reserved-memory/etf1_trace@0";
		etf2_trace = "/reserved-memory/etf2_trace@0";
		etf3_trace = "/reserved-memory/etf3_trace@0";
		etf4_trace = "/reserved-memory/etf4_trace@0";
		etf5_trace = "/reserved-memory/etf5_trace@0";
		etf6_trace = "/reserved-memory/etf6_trace@0";
		etf7_trace = "/reserved-memory/etf7_trace@0";
		CPU0 = "/cpus/cpu@0";
		L2_0 = "/cpus/cpu@0/l2-cache";
		CPU1 = "/cpus/cpu@10000";
		L2_10000 = "/cpus/cpu@10000/l2-cache";
		CPU2 = "/cpus/cpu@20000";
		L2_20000 = "/cpus/cpu@20000/l2-cache";
		CPU3 = "/cpus/cpu@30000";
		L2_30000 = "/cpus/cpu@30000/l2-cache";
		CPU4 = "/cpus/cpu@40000";
		L2_40000 = "/cpus/cpu@40000/l2-cache";
		CPU5 = "/cpus/cpu@50000";
		L2_50000 = "/cpus/cpu@50000/l2-cache";
		CPU6 = "/cpus/cpu@60000";
		L2_60000 = "/cpus/cpu@60000/l2-cache";
		CPU7 = "/cpus/cpu@70000";
		L2_70000 = "/cpus/cpu@70000/l2-cache";
		octeontx2_L3 = "/l3-cache";
		gic0 = "/interrupt-controller@801000000000";
		its = "/interrupt-controller@801000000000/gic-its@801000040000";
		soc_0 = "/soc@0";
		cpu_scp_lpri = "/soc@0/sram@26,0/scp-shmem@0";
		scp_to_cpu = "/soc@0/sram@36,0/scp-shmem@0";
		refclkuaa = "/soc@0/refclkuaa";
		ioclk = "/soc@0/ioclk";
		sclk = "/soc@0/sclk";
		sdmclk = "/soc@0/sdmclk";
		uaa0 = "/soc@0/serial@87e028000000";
		ttymem = "/soc@0/ttymem";
		bootcmd = "/soc@0/pci-bootcmd@0x027ff000";
		smmu0 = "/soc@0/smmu@830000000000";
		mmc = "/soc@0/sdhci@824000000000";
		spi_6_0 = "/soc@0/spi@804000000000";
		firmware_flash0 = "/soc@0/spi@804000000000/flash@0";
		spi_7_0 = "/soc@0/spi@805000000000";
		ecam0 = "/soc@0/pci@878000000000";
		mrml_bridge = "/soc@0/pci@878000000000/mrml-bridge0@1,0";
		mdio0 = "/soc@0/pci@878000000000/mrml-bridge0@1,0/mdio-nexus@1,3/mdio0@87e005003800";
		mdio1 = "/soc@0/pci@878000000000/mrml-bridge0@1,0/mdio-nexus@1,3/mdio1@87e005003880";
		xfi10 = "/soc@0/pci@878000000000/mrml-bridge0@1,0/mdio-nexus@1,3/mdio1@87e005003880/xfi10";
		i2c_24_0 = "/soc@0/pci@878000000000/mrml-bridge0@1,0/i2c@24,0";
		psu_io = "/soc@0/pci@878000000000/mrml-bridge0@1,0/i2c@24,0/pca9575@23";
		i2c_24_1 = "/soc@0/pci@878000000000/mrml-bridge0@1,0/i2c@24,1";
		s35390a = "/soc@0/pci@878000000000/mrml-bridge0@1,0/i2c@24,1/i2c_mux@72/i2c@2/s35390a@30";
		i2c_24_2 = "/soc@0/pci@878000000000/mrml-bridge0@1,0/i2c@24,2";
		hdd_pwren_det_l = "/soc@0/pci@878000000000/mrml-bridge0@1,0/i2c@24,2/i2c_mux@70/i2c@4/pca9575@24";
		hdd_pwren_det_r = "/soc@0/pci@878000000000/mrml-bridge0@1,0/i2c@24,2/i2c_mux@70/i2c@4/pca9575@25";
		hdd_fault_l = "/soc@0/pci@878000000000/mrml-bridge0@1,0/i2c@24,2/i2c_mux@70/i2c@4/pca9575@26";
		hdd_fault_r = "/soc@0/pci@878000000000/mrml-bridge0@1,0/i2c@24,2/i2c_mux@70/i2c@4/pca9575@27";
		hdd_int = "/soc@0/pci@878000000000/mrml-bridge0@1,0/i2c@24,2/i2c_mux@70/i2c@5/pca9575@28";
		i2c_24_3 = "/soc@0/pci@878000000000/mrml-bridge0@1,0/i2c@24,3";
		i2c_24_4 = "/soc@0/pci@878000000000/mrml-bridge0@1,0/i2c@24,4";
		fio = "/soc@0/pci@878000000000/mrml-bridge0@1,0/i2c@24,4/i2c_mux@71/i2c@3/pca9555@20";
		sfp_io = "/soc@0/pci@878000000000/mrml-bridge0@1,0/i2c@24,4/pca9575@27";
		i2c_24_5 = "/soc@0/pci@878000000000/mrml-bridge0@1,0/i2c@24,5";
		i2c_24_6 = "/soc@0/pci@878000000000/mrml-bridge0@1,0/i2c@24,6";
		i2c_24_7 = "/soc@0/pci@878000000000/mrml-bridge0@1,0/i2c@24,7";
		i2c_24_8 = "/soc@0/pci@878000000000/mrml-bridge0@1,0/i2c@24,8";
		i2c_24_9 = "/soc@0/pci@878000000000/mrml-bridge0@1,0/i2c@24,9";
		i2c_24_10 = "/soc@0/pci@878000000000/mrml-bridge0@1,0/i2c@24,10";
		i2c_24_11 = "/soc@0/pci@878000000000/mrml-bridge0@1,0/i2c@24,11";
		rpm_0 = "/soc@0/pci@878000000000/mrml-bridge0@1,0/rpm@0";
		ethernetA0 = "/soc@0/pci@878000000000/mrml-bridge0@1,0/rpm@0/10g@00";
		rpm_1 = "/soc@0/pci@878000000000/mrml-bridge0@1,0/rpm@1";
		rpm_2 = "/soc@0/pci@878000000000/mrml-bridge0@1,0/rpm@2";
		ethernetC0 = "/soc@0/pci@878000000000/mrml-bridge0@1,0/rpm@2/10g@20";
		ethernetC1 = "/soc@0/pci@878000000000/mrml-bridge0@1,0/rpm@2/10g@21";
		gpio_17_0 = "/soc@0/pci@878000000000/gpio0@17,0";
		mailbox = "/soc@0/pci@878000000000/mailbox@28,0";
		ecam2 = "/soc@0/pci@878020000000";
		pem0 = "/soc@0/pci@878030000000";
		pem1 = "/soc@0/pci@878040000000";
		pem2 = "/soc@0/pci@878050000000";
		pem3 = "/soc@0/pci@878060000000";
		pem4 = "/soc@0/pci@878070000000";
		pem5 = "/soc@0/pci@878080000000";
		uaa1 = "/soc@0/serial@87e029000000";
		uaa2 = "/soc@0/serial@87e02a000000";
		uaa3 = "/soc@0/serial@87e02b000000";
		uaa4 = "/soc@0/serial@87e02c000000";
		uaa5 = "/soc@0/serial@87e02d000000";
		uaa6 = "/soc@0/serial@87e02e000000";
		uaa7 = "/soc@0/serial@87e02f000000";
		ecam1 = "/soc@0/pci@878010000000";
		ete0 = "/soc@0/ete0";
		ete0_out = "/soc@0/ete0/out-ports/port/endpoint";
		etf0 = "/soc@0/etf0@87a004010000";
		etf0_in = "/soc@0/etf0@87a004010000/in-ports/port/endpoint";
		etf0_out = "/soc@0/etf0@87a004010000/out-ports/port/endpoint";
		ete1 = "/soc@0/ete1";
		ete1_out = "/soc@0/ete1/out-ports/port/endpoint";
		etf1 = "/soc@0/etf1@87a004110000";
		etf1_in = "/soc@0/etf1@87a004110000/in-ports/port/endpoint";
		etf1_out = "/soc@0/etf1@87a004110000/out-ports/port/endpoint";
		ete2 = "/soc@0/ete2";
		ete2_out = "/soc@0/ete2/out-ports/port/endpoint";
		etf2 = "/soc@0/etf2@87a004210000";
		etf2_in = "/soc@0/etf2@87a004210000/in-ports/port/endpoint";
		etf2_out = "/soc@0/etf2@87a004210000/out-ports/port/endpoint";
		ete3 = "/soc@0/ete3";
		ete3_out = "/soc@0/ete3/out-ports/port/endpoint";
		etf3 = "/soc@0/etf3@87a004310000";
		etf3_in = "/soc@0/etf3@87a004310000/in-ports/port/endpoint";
		etf3_out = "/soc@0/etf3@87a004310000/out-ports/port/endpoint";
		ete4 = "/soc@0/ete4";
		ete4_out = "/soc@0/ete4/out-ports/port/endpoint";
		etf4 = "/soc@0/etf4@87a004410000";
		etf4_in = "/soc@0/etf4@87a004410000/in-ports/port/endpoint";
		etf4_out = "/soc@0/etf4@87a004410000/out-ports/port/endpoint";
		ete5 = "/soc@0/ete5";
		ete5_out = "/soc@0/ete5/out-ports/port/endpoint";
		etf5 = "/soc@0/etf5@87a004510000";
		etf5_in = "/soc@0/etf5@87a004510000/in-ports/port/endpoint";
		etf5_out = "/soc@0/etf5@87a004510000/out-ports/port/endpoint";
		ete6 = "/soc@0/ete6";
		ete6_out = "/soc@0/ete6/out-ports/port/endpoint";
		etf6 = "/soc@0/etf6@87a004610000";
		etf6_in = "/soc@0/etf6@87a004610000/in-ports/port/endpoint";
		etf6_out = "/soc@0/etf6@87a004610000/out-ports/port/endpoint";
		ete7 = "/soc@0/ete7";
		ete7_out = "/soc@0/ete7/out-ports/port/endpoint";
		etf7 = "/soc@0/etf7@87a004710000";
		etf7_in = "/soc@0/etf7@87a004710000/in-ports/port/endpoint";
		etf7_out = "/soc@0/etf7@87a004710000/out-ports/port/endpoint";
		static_funnel_out = "/soc@0/st_funnel/out-ports/port/endpoint";
		static_funnel_in0 = "/soc@0/st_funnel/in-ports/port@0/endpoint";
		static_funnel_in1 = "/soc@0/st_funnel/in-ports/port@1/endpoint";
		static_funnel_in2 = "/soc@0/st_funnel/in-ports/port@2/endpoint";
		static_funnel_in3 = "/soc@0/st_funnel/in-ports/port@3/endpoint";
		static_funnel_in4 = "/soc@0/st_funnel/in-ports/port@4/endpoint";
		static_funnel_in5 = "/soc@0/st_funnel/in-ports/port@5/endpoint";
		static_funnel_in6 = "/soc@0/st_funnel/in-ports/port@6/endpoint";
		static_funnel_in7 = "/soc@0/st_funnel/in-ports/port@7/endpoint";
		shared_etf_in = "/soc@0/sh_etf@87a100050000/in-ports/port/endpoint";
		shared_etf_out = "/soc@0/sh_etf@87a100050000/out-ports/port/endpoint";
		sh_etr = "/soc@0/sh_etr@87a100060000";
		shared_etr_in = "/soc@0/sh_etr@87a100060000/in-ports/port/endpoint";
		scmi_dvfs = "/firmware/scmi/protocol@13";
		scmi_clk = "/firmware/scmi/protocol@14";
		scmi_sensors0 = "/firmware/scmi/protocol@15";
		aliases = "/aliases";
		vqmmc_supply_1v8 = "/vqmmc_supply_1v8";
		mmc_supply_1v8 = "/mmc_supply_1v8";
		reset_button_gpio = "/soc@0/pci@878000000000/gpio0@17,0";
	};
};
